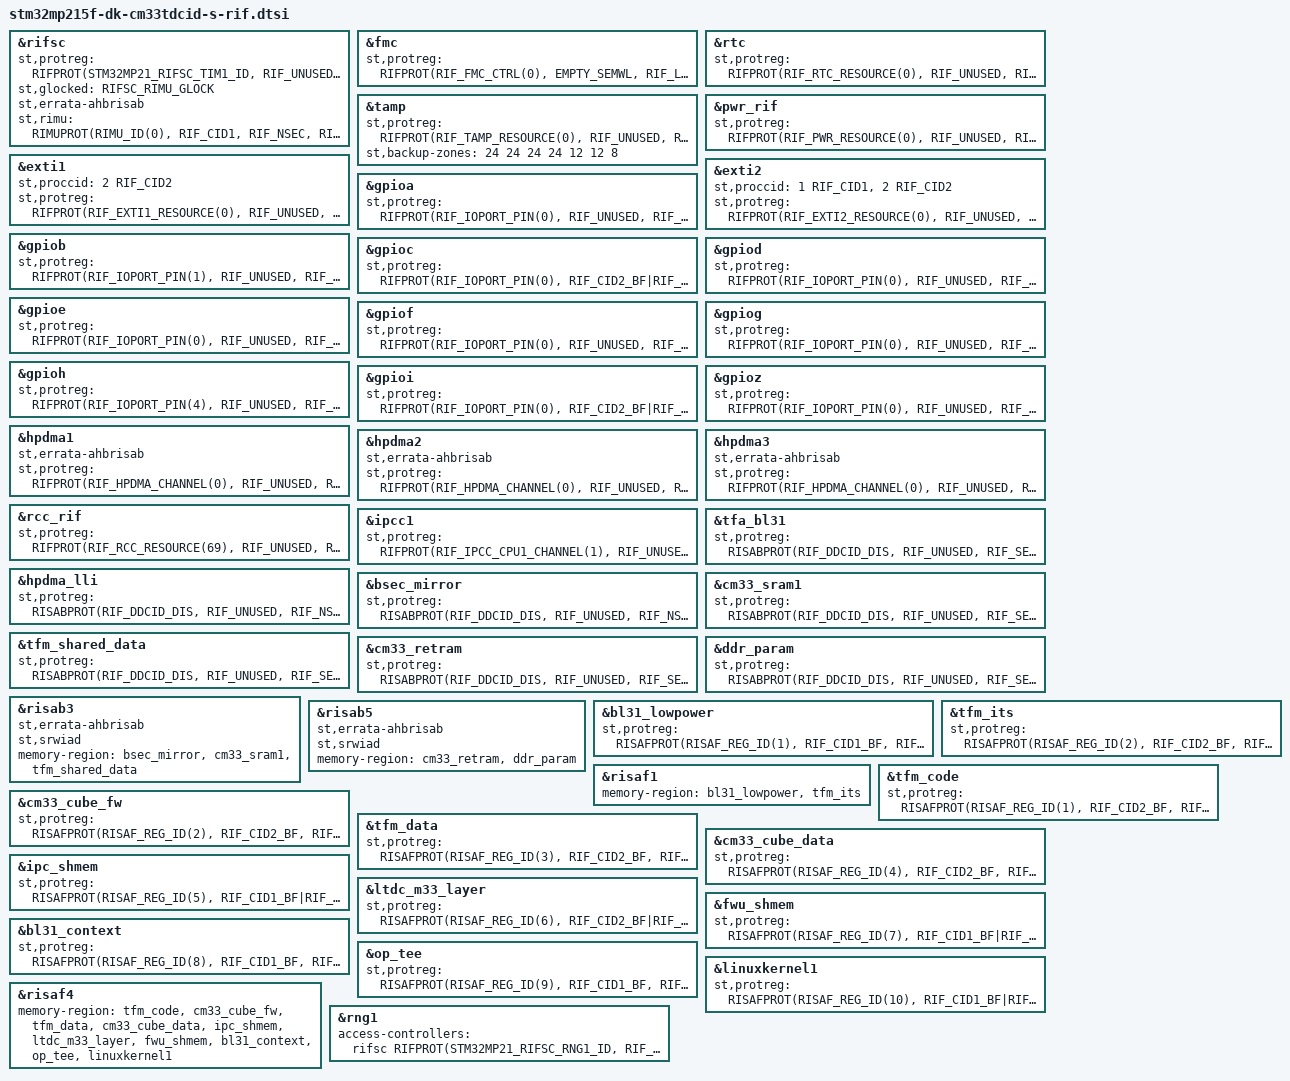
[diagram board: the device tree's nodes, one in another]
/*
 * Copyright (c) 2026, STMicroelectronics - All Rights Reserved
 *
 * SPDX-License-Identifier: Apache-2.0
 */

&rifsc {
	st,protreg = <
		RIFPROT(STM32MP21_RIFSC_TIM1_ID, RIF_UNUSED, RIF_UNLOCK, RIF_NSEC, RIF_PRIV, RIF_CID1, RIF_SEM_DIS, RIF_CFEN)
		RIFPROT(STM32MP21_RIFSC_TIM2_ID, RIF_UNUSED, RIF_UNLOCK, RIF_SEC, RIF_PRIV, RIF_CID2, RIF_SEM_DIS, RIF_CFEN)
		RIFPROT(STM32MP21_RIFSC_TIM3_ID, RIF_UNUSED, RIF_UNLOCK, RIF_NSEC, RIF_NPRIV, RIF_CID2, RIF_SEM_DIS, RIF_CFEN)
		RIFPROT(STM32MP21_RIFSC_TIM4_ID, RIF_UNUSED, RIF_UNLOCK, RIF_NSEC, RIF_PRIV, RIF_CID1, RIF_SEM_DIS, RIF_CFEN)
		RIFPROT(STM32MP21_RIFSC_TIM5_ID, RIF_UNUSED, RIF_UNLOCK, RIF_NSEC, RIF_PRIV, RIF_CID1, RIF_SEM_DIS, RIF_CFEN)
		RIFPROT(STM32MP21_RIFSC_TIM6_ID, RIF_UNUSED, RIF_UNLOCK, RIF_NSEC, RIF_NPRIV, RIF_CID2, RIF_SEM_DIS, RIF_CFEN)
		RIFPROT(STM32MP21_RIFSC_TIM7_ID, RIF_UNUSED, RIF_UNLOCK, RIF_NSEC, RIF_PRIV, RIF_CID1, RIF_SEM_DIS, RIF_CFEN)
		RIFPROT(STM32MP21_RIFSC_TIM8_ID, RIF_UNUSED, RIF_UNLOCK, RIF_NSEC, RIF_NPRIV, RIF_CID2, RIF_SEM_DIS, RIF_CFEN)
		RIFPROT(STM32MP21_RIFSC_TIM10_ID, RIF_UNUSED, RIF_UNLOCK, RIF_NSEC, RIF_PRIV, RIF_CID1, RIF_SEM_DIS, RIF_CFEN)
		RIFPROT(STM32MP21_RIFSC_TIM11_ID, RIF_UNUSED, RIF_UNLOCK, RIF_NSEC, RIF_PRIV, RIF_CID1, RIF_SEM_DIS, RIF_CFEN)
		RIFPROT(STM32MP21_RIFSC_TIM12_ID, RIF_UNUSED, RIF_UNLOCK, RIF_NSEC, RIF_PRIV, RIF_CID1, RIF_SEM_DIS, RIF_CFEN)
		RIFPROT(STM32MP21_RIFSC_TIM13_ID, RIF_UNUSED, RIF_UNLOCK, RIF_NSEC, RIF_PRIV, RIF_CID1, RIF_SEM_DIS, RIF_CFEN)
		RIFPROT(STM32MP21_RIFSC_TIM14_ID, RIF_UNUSED, RIF_UNLOCK, RIF_NSEC, RIF_PRIV, RIF_CID1, RIF_SEM_DIS, RIF_CFEN)
		RIFPROT(STM32MP21_RIFSC_TIM15_ID, RIF_UNUSED, RIF_UNLOCK, RIF_NSEC, RIF_PRIV, RIF_CID1, RIF_SEM_DIS, RIF_CFEN)
		RIFPROT(STM32MP21_RIFSC_TIM16_ID, RIF_UNUSED, RIF_UNLOCK, RIF_NSEC, RIF_PRIV, RIF_CID1, RIF_SEM_DIS, RIF_CFEN)
		RIFPROT(STM32MP21_RIFSC_TIM17_ID, RIF_UNUSED, RIF_UNLOCK, RIF_NSEC, RIF_PRIV, RIF_CID1, RIF_SEM_DIS, RIF_CFEN)
		RIFPROT(STM32MP21_RIFSC_LPTIM1_ID, RIF_UNUSED, RIF_UNLOCK, RIF_SEC, RIF_PRIV, RIF_CID2, RIF_SEM_DIS, RIF_CFEN)
		RIFPROT(STM32MP21_RIFSC_LPTIM2_ID, RIF_UNUSED, RIF_UNLOCK, RIF_NSEC, RIF_PRIV, RIF_CID1, RIF_SEM_DIS, RIF_CFEN)
		RIFPROT(STM32MP21_RIFSC_LPTIM3_ID, RIF_UNUSED, RIF_UNLOCK, RIF_NSEC, RIF_PRIV, RIF_CID1, RIF_SEM_DIS, RIF_CFEN)
		RIFPROT(STM32MP21_RIFSC_LPTIM4_ID, RIF_UNUSED, RIF_UNLOCK, RIF_NSEC, RIF_NPRIV, RIF_CID2, RIF_SEM_DIS, RIF_CFEN)
		RIFPROT(STM32MP21_RIFSC_LPTIM5_ID, RIF_UNUSED, RIF_UNLOCK, RIF_NSEC, RIF_PRIV, RIF_CID1, RIF_SEM_DIS, RIF_CFEN)
		RIFPROT(STM32MP21_RIFSC_SPI1_ID, RIF_UNUSED, RIF_UNLOCK, RIF_NSEC, RIF_NPRIV, RIF_CID2, RIF_SEM_DIS, RIF_CFEN)
		RIFPROT(STM32MP21_RIFSC_SPI2_ID, EMPTY_SEMWL, RIF_LOCK, RIF_NSEC, RIF_NPRIV, RIF_UNUSED, RIF_SEM_EN, RIF_CFEN)
		RIFPROT(STM32MP21_RIFSC_SPI3_ID, EMPTY_SEMWL, RIF_LOCK, RIF_NSEC, RIF_NPRIV, RIF_UNUSED, RIF_SEM_EN, RIF_CFEN)
		RIFPROT(STM32MP21_RIFSC_SPI4_ID, EMPTY_SEMWL, RIF_LOCK, RIF_NSEC, RIF_NPRIV, RIF_UNUSED, RIF_SEM_EN, RIF_CFEN)
		RIFPROT(STM32MP21_RIFSC_SPI5_ID, EMPTY_SEMWL, RIF_LOCK, RIF_NSEC, RIF_NPRIV, RIF_UNUSED, RIF_SEM_EN, RIF_CFEN)
		RIFPROT(STM32MP21_RIFSC_SPI6_ID, EMPTY_SEMWL, RIF_LOCK, RIF_NSEC, RIF_NPRIV, RIF_UNUSED, RIF_SEM_EN, RIF_CFEN)
		RIFPROT(STM32MP21_RIFSC_SPDIFRX_ID, EMPTY_SEMWL, RIF_LOCK, RIF_NSEC, RIF_NPRIV, RIF_UNUSED, RIF_SEM_EN, RIF_CFEN)
		RIFPROT(STM32MP21_RIFSC_USART1_ID, RIF_UNUSED, RIF_UNLOCK, RIF_NSEC, RIF_PRIV, RIF_CID1, RIF_SEM_DIS, RIF_CFEN)
		RIFPROT(STM32MP21_RIFSC_USART2_ID, RIF_UNUSED, RIF_UNLOCK, RIF_NSEC, RIF_PRIV, RIF_CID1, RIF_SEM_DIS, RIF_CFEN)
		RIFPROT(STM32MP21_RIFSC_USART3_ID, EMPTY_SEMWL, RIF_LOCK, RIF_NSEC, RIF_NPRIV, RIF_UNUSED, RIF_SEM_EN, RIF_CFEN)
		RIFPROT(STM32MP21_RIFSC_UART4_ID, RIF_UNUSED, RIF_UNLOCK, RIF_NSEC, RIF_NPRIV, RIF_CID2, RIF_SEM_DIS, RIF_CFEN)
		RIFPROT(STM32MP21_RIFSC_UART5_ID, EMPTY_SEMWL, RIF_LOCK, RIF_NSEC, RIF_NPRIV, RIF_UNUSED, RIF_SEM_EN, RIF_CFEN)
		RIFPROT(STM32MP21_RIFSC_USART6_ID, RIF_UNUSED, RIF_LOCK, RIF_NSEC, RIF_PRIV, RIF_CID1, RIF_SEM_DIS, RIF_CFEN)
		RIFPROT(STM32MP21_RIFSC_UART7_ID, EMPTY_SEMWL, RIF_LOCK, RIF_NSEC, RIF_NPRIV, RIF_UNUSED, RIF_SEM_EN, RIF_CFEN)
		RIFPROT(STM32MP21_RIFSC_LPUART1_ID, EMPTY_SEMWL, RIF_LOCK, RIF_NSEC, RIF_NPRIV, RIF_UNUSED, RIF_SEM_EN, RIF_CFEN)
		RIFPROT(STM32MP21_RIFSC_I2C1_ID, EMPTY_SEMWL, RIF_LOCK, RIF_NSEC, RIF_NPRIV, RIF_UNUSED, RIF_SEM_EN, RIF_CFEN)
		RIFPROT(STM32MP21_RIFSC_I2C2_ID, RIF_UNUSED, RIF_UNLOCK, RIF_NSEC, RIF_PRIV, RIF_CID1, RIF_SEM_DIS, RIF_CFEN)
		RIFPROT(STM32MP21_RIFSC_I2C3_ID, RIF_UNUSED, RIF_UNLOCK, RIF_SEC, RIF_PRIV, RIF_CID2, RIF_SEM_DIS, RIF_CFEN)
		RIFPROT(STM32MP21_RIFSC_SAI1_ID, RIF_UNUSED, RIF_UNLOCK, RIF_NSEC, RIF_PRIV, RIF_CID1, RIF_SEM_DIS, RIF_CFEN)
		RIFPROT(STM32MP21_RIFSC_SAI2_ID, RIF_UNUSED, RIF_UNLOCK, RIF_NSEC, RIF_PRIV, RIF_CID1, RIF_SEM_DIS, RIF_CFEN)
		RIFPROT(STM32MP21_RIFSC_SAI3_ID, EMPTY_SEMWL, RIF_LOCK, RIF_NSEC, RIF_NPRIV, RIF_UNUSED, RIF_SEM_EN, RIF_CFEN)
		RIFPROT(STM32MP21_RIFSC_SAI4_ID, EMPTY_SEMWL, RIF_LOCK, RIF_NSEC, RIF_NPRIV, RIF_UNUSED, RIF_SEM_EN, RIF_CFEN)
		RIFPROT(STM32MP21_RIFSC_MDF1_ID, RIF_UNUSED, RIF_UNLOCK, RIF_NSEC, RIF_PRIV, RIF_CID1, RIF_SEM_DIS, RIF_CFEN)
		RIFPROT(STM32MP21_RIFSC_FDCAN_ID, EMPTY_SEMWL, RIF_LOCK, RIF_NSEC, RIF_NPRIV, RIF_UNUSED, RIF_SEM_EN, RIF_CFEN)
		RIFPROT(STM32MP21_RIFSC_HDP_ID, EMPTY_SEMWL, RIF_LOCK, RIF_NSEC, RIF_NPRIV, RIF_UNUSED, RIF_SEM_EN, RIF_CFEN)
		RIFPROT(STM32MP21_RIFSC_ADC1_ID, RIF_UNUSED, RIF_UNLOCK, RIF_NSEC, RIF_PRIV, RIF_CID1, RIF_SEM_DIS, RIF_CFEN)
		RIFPROT(STM32MP21_RIFSC_ADC2_ID, RIF_UNUSED, RIF_UNLOCK, RIF_NSEC, RIF_PRIV, RIF_CID1, RIF_SEM_DIS, RIF_CFEN)
		RIFPROT(STM32MP21_RIFSC_ETH1_ID, RIF_UNUSED, RIF_UNLOCK, RIF_NSEC, RIF_PRIV, RIF_CID1, RIF_SEM_DIS, RIF_CFEN)
		RIFPROT(STM32MP21_RIFSC_ETH2_ID, EMPTY_SEMWL, RIF_LOCK, RIF_NSEC, RIF_NPRIV, RIF_UNUSED, RIF_SEM_EN, RIF_CFEN)
		RIFPROT(STM32MP21_RIFSC_USBH_ID, RIF_UNUSED, RIF_UNLOCK, RIF_NSEC, RIF_PRIV, RIF_CID1, RIF_SEM_DIS, RIF_CFEN)
		RIFPROT(STM32MP21_RIFSC_OTG_HS_ID, RIF_UNUSED, RIF_UNLOCK, RIF_NSEC, RIF_PRIV, RIF_CID1, RIF_SEM_DIS, RIF_CFEN)
		RIFPROT(STM32MP21_RIFSC_DDRPERFM_ID, RIF_UNUSED, RIF_UNLOCK, RIF_NSEC, RIF_PRIV, RIF_CID1, RIF_SEM_DIS, RIF_CFEN)
		RIFPROT(STM32MP21_RIFSC_STGEN_ID, RIF_UNUSED, RIF_UNLOCK, RIF_SEC, RIF_PRIV, RIF_CID1, RIF_SEM_DIS, RIF_CFEN)
		RIFPROT(STM32MP21_RIFSC_OCTOSPI1_ID, EMPTY_SEMWL, RIF_LOCK, RIF_NSEC, RIF_NPRIV, RIF_UNUSED, RIF_SEM_EN, RIF_CFEN)
		RIFPROT(STM32MP21_RIFSC_OTFDEC1_ID, EMPTY_SEMWL, RIF_LOCK, RIF_NSEC, RIF_NPRIV, RIF_UNUSED, RIF_SEM_EN, RIF_CFEN)
		RIFPROT(STM32MP21_RIFSC_SDMMC1_ID, RIF_UNUSED, RIF_UNLOCK, RIF_NSEC, RIF_PRIV, RIF_CID1, RIF_SEM_DIS, RIF_CFEN)
		RIFPROT(STM32MP21_RIFSC_SDMMC2_ID, RIF_UNUSED, RIF_UNLOCK, RIF_NSEC, RIF_PRIV, RIF_CID1, RIF_SEM_DIS, RIF_CFEN)
		RIFPROT(STM32MP21_RIFSC_SDMMC3_ID, RIF_UNUSED, RIF_UNLOCK, RIF_NSEC, RIF_PRIV, RIF_CID1, RIF_SEM_DIS, RIF_CFEN)
		RIFPROT(STM32MP21_RIFSC_LTDC_CMN_ID, RIF_CID1_BF|RIF_CID2_BF, RIF_UNLOCK, RIF_NSEC, RIF_NPRIV, RIF_UNUSED, RIF_SEM_EN, RIF_CFEN)
		RIFPROT(STM32MP21_RIFSC_LTDC_L1L2_ID, RIF_UNUSED, RIF_UNLOCK, RIF_NSEC, RIF_PRIV, RIF_CID1, RIF_SEM_DIS, RIF_CFEN)
		RIFPROT(STM32MP21_RIFSC_LTDC_L3_ID, RIF_UNUSED, RIF_UNLOCK, RIF_NSEC, RIF_NPRIV, RIF_CID2, RIF_SEM_DIS, RIF_CFEN)
		RIFPROT(STM32MP21_RIFSC_CSI_ID, RIF_UNUSED, RIF_UNLOCK, RIF_NSEC, RIF_PRIV, RIF_CID1, RIF_SEM_DIS, RIF_CFEN)
		RIFPROT(STM32MP21_RIFSC_DCMIPP_ID, RIF_UNUSED, RIF_UNLOCK, RIF_NSEC, RIF_PRIV, RIF_CID1, RIF_SEM_DIS, RIF_CFEN)
		RIFPROT(STM32MP21_RIFSC_DCMI_PSSI_ID, EMPTY_SEMWL, RIF_LOCK, RIF_NSEC, RIF_NPRIV, RIF_UNUSED, RIF_SEM_EN, RIF_CFEN)
		RIFPROT(STM32MP21_RIFSC_RESERVED_91_ID, RIF_CID1_BF|RIF_CID2_BF, RIF_LOCK, RIF_SEC, RIF_PRIV, RIF_UNUSED, RIF_SEM_EN, RIF_CFEN)
		RIFPROT(STM32MP21_RIFSC_RNG1_ID, RIF_CID1_BF|RIF_CID2_BF, RIF_LOCK, RIF_SEC, RIF_PRIV, RIF_UNUSED, RIF_SEM_EN, RIF_CFEN)
		RIFPROT(STM32MP21_RIFSC_RNG2_ID, RIF_UNUSED, RIF_UNLOCK, RIF_SEC, RIF_PRIV, RIF_CID1, RIF_SEM_DIS, RIF_CFEN)
		RIFPROT(STM32MP21_RIFSC_PKA_ID, RIF_CID1_BF|RIF_CID2_BF, RIF_LOCK, RIF_SEC, RIF_PRIV, RIF_UNUSED, RIF_SEM_EN, RIF_CFEN)
		RIFPROT(STM32MP21_RIFSC_SAES_ID, RIF_CID1_BF|RIF_CID2_BF, RIF_LOCK, RIF_SEC, RIF_PRIV, RIF_UNUSED, RIF_SEM_EN, RIF_CFEN)
		RIFPROT(STM32MP21_RIFSC_HASH1_ID, RIF_CID1_BF|RIF_CID2_BF, RIF_LOCK, RIF_SEC, RIF_PRIV, RIF_UNUSED, RIF_SEM_EN, RIF_CFEN)
		RIFPROT(STM32MP21_RIFSC_HASH2_ID, RIF_UNUSED, RIF_UNLOCK, RIF_SEC, RIF_PRIV, RIF_CID1, RIF_SEM_DIS, RIF_CFEN)
		RIFPROT(STM32MP21_RIFSC_CRYP1_ID, RIF_CID1_BF|RIF_CID2_BF, RIF_LOCK, RIF_SEC, RIF_PRIV, RIF_UNUSED, RIF_SEM_EN, RIF_CFEN)
		RIFPROT(STM32MP21_RIFSC_CRYP2_ID, RIF_CID1_BF|RIF_CID2_BF, RIF_UNLOCK, RIF_NSEC, RIF_NPRIV, RIF_UNUSED, RIF_SEM_EN, RIF_CFEN)
		RIFPROT(STM32MP21_RIFSC_IWDG1_ID, RIF_UNUSED, RIF_UNLOCK, RIF_SEC, RIF_PRIV, RIF_CID1, RIF_SEM_DIS, RIF_CFEN)
		RIFPROT(STM32MP21_RIFSC_IWDG2_ID, RIF_UNUSED, RIF_UNLOCK, RIF_NSEC, RIF_PRIV, RIF_CID1, RIF_SEM_DIS, RIF_CFEN)
		RIFPROT(STM32MP21_RIFSC_IWDG3_ID, RIF_UNUSED, RIF_UNLOCK, RIF_SEC, RIF_PRIV, RIF_CID2, RIF_SEM_DIS, RIF_CFEN)
		RIFPROT(STM32MP21_RIFSC_IWDG4_ID, RIF_UNUSED, RIF_UNLOCK, RIF_NSEC, RIF_NPRIV, RIF_CID2, RIF_SEM_DIS, RIF_CFEN)
		RIFPROT(STM32MP21_RIFSC_WWDG1_ID, RIF_UNUSED, RIF_UNLOCK, RIF_NSEC, RIF_NPRIV, RIF_CID2, RIF_SEM_DIS, RIF_CFEN)
		RIFPROT(STM32MP21_RIFSC_VREFBUF_ID, RIF_UNUSED, RIF_UNLOCK, RIF_SEC, RIF_PRIV, RIF_CID2, RIF_SEM_DIS, RIF_CFEN)
		RIFPROT(STM32MP21_RIFSC_DTS_ID, RIF_UNUSED, RIF_UNLOCK, RIF_NSEC, RIF_PRIV, RIF_CID1, RIF_SEM_DIS, RIF_CFEN)
		RIFPROT(STM32MP21_RIFSC_RAMCFG_ID, RIF_UNUSED, RIF_UNLOCK, RIF_SEC, RIF_PRIV, RIF_CID2, RIF_SEM_DIS, RIF_CFEN)
		RIFPROT(STM32MP21_RIFSC_CRC_ID, RIF_UNUSED, RIF_UNLOCK, RIF_SEC, RIF_PRIV, RIF_CID2, RIF_SEM_DIS, RIF_CFEN)
		RIFPROT(STM32MP21_RIFSC_SERC_ID, RIF_UNUSED, RIF_UNLOCK, RIF_SEC, RIF_PRIV, RIF_CID2, RIF_SEM_DIS, RIF_CFEN)
		RIFPROT(STM32MP21_RIFSC_I3C1_ID, RIF_UNUSED, RIF_UNLOCK, RIF_NSEC, RIF_PRIV, RIF_CID1, RIF_SEM_DIS, RIF_CFEN)
		RIFPROT(STM32MP21_RIFSC_I3C2_ID, RIF_UNUSED, RIF_UNLOCK, RIF_NSEC, RIF_NPRIV, RIF_CID2, RIF_SEM_DIS, RIF_CFEN)
		RIFPROT(STM32MP21_RIFSC_I3C3_ID, EMPTY_SEMWL, RIF_LOCK, RIF_NSEC, RIF_NPRIV, RIF_UNUSED, RIF_SEM_EN, RIF_CFEN)
		RIFPROT(STM32MP21_RIFSC_ICACHE_DCACHE_ID, RIF_UNUSED, RIF_UNLOCK, RIF_NSEC, RIF_NPRIV, RIF_CID2, RIF_SEM_DIS, RIF_CFEN)
	>;
	st,glocked = <RIFSC_RIMU_GLOCK>;
};

&fmc {
	st,protreg = <
		RIFPROT(RIF_FMC_CTRL(0), EMPTY_SEMWL, RIF_LOCK, RIF_NSEC, RIF_NPRIV, RIF_UNUSED, RIF_SEM_EN, RIF_CFEN)
		RIFPROT(RIF_FMC_CTRL(1), EMPTY_SEMWL, RIF_LOCK, RIF_NSEC, RIF_NPRIV, RIF_UNUSED, RIF_SEM_EN, RIF_CFEN)
		RIFPROT(RIF_FMC_CTRL(2), EMPTY_SEMWL, RIF_LOCK, RIF_NSEC, RIF_NPRIV, RIF_UNUSED, RIF_SEM_EN, RIF_CFEN)
		RIFPROT(RIF_FMC_CTRL(3), EMPTY_SEMWL, RIF_LOCK, RIF_NSEC, RIF_NPRIV, RIF_UNUSED, RIF_SEM_EN, RIF_CFEN)
		RIFPROT(RIF_FMC_CTRL(4), EMPTY_SEMWL, RIF_LOCK, RIF_NSEC, RIF_NPRIV, RIF_UNUSED, RIF_SEM_EN, RIF_CFEN)
		RIFPROT(RIF_FMC_CTRL(5), EMPTY_SEMWL, RIF_LOCK, RIF_NSEC, RIF_NPRIV, RIF_UNUSED, RIF_SEM_EN, RIF_CFEN)
	>;
};

&rtc {
	st,protreg = <
		RIFPROT(RIF_RTC_RESOURCE(0), RIF_UNUSED, RIF_UNLOCK, RIF_NSEC, RIF_PRIV, RIF_CID1, RIF_SEM_DIS, RIF_CFEN)
		RIFPROT(RIF_RTC_RESOURCE(1), RIF_UNUSED, RIF_UNLOCK, RIF_NSEC, RIF_NPRIV, RIF_CID2, RIF_SEM_DIS, RIF_CFEN)
		RIFPROT(RIF_RTC_RESOURCE(2), RIF_UNUSED, RIF_UNLOCK, RIF_NSEC, RIF_PRIV, RIF_CID1, RIF_SEM_DIS, RIF_CFEN)
		RIFPROT(RIF_RTC_RESOURCE(3), RIF_UNUSED, RIF_UNLOCK, RIF_NSEC, RIF_PRIV, RIF_CID1, RIF_SEM_DIS, RIF_CFEN)
		RIFPROT(RIF_RTC_RESOURCE(4), RIF_UNUSED, RIF_UNLOCK, RIF_NSEC, RIF_PRIV, RIF_CID1, RIF_SEM_DIS, RIF_CFEN)
		RIFPROT(RIF_RTC_RESOURCE(5), RIF_UNUSED, RIF_UNLOCK, RIF_NSEC, RIF_PRIV, RIF_CID1, RIF_SEM_DIS, RIF_CFEN)
	>;
};

&tamp {
	st,protreg = <
		RIFPROT(RIF_TAMP_RESOURCE(0), RIF_UNUSED, RIF_UNLOCK, RIF_SEC, RIF_PRIV, RIF_CID2, RIF_SEM_DIS, RIF_CFEN)
		RIFPROT(RIF_TAMP_RESOURCE(1), RIF_UNUSED, RIF_UNLOCK, RIF_SEC, RIF_PRIV, RIF_CID1, RIF_SEM_DIS, RIF_CFEN)
		RIFPROT(RIF_TAMP_RESOURCE(2), RIF_UNUSED, RIF_UNLOCK, RIF_SEC, RIF_PRIV, RIF_CID2, RIF_SEM_DIS, RIF_CFEN)
	>;
	st,backup-zones = <24 24 24 24 12 12 8>;
};

&pwr_rif {
	st,protreg = <
		RIFPROT(RIF_PWR_RESOURCE(0), RIF_UNUSED, RIF_UNLOCK, RIF_SEC, RIF_PRIV, RIF_CID2, RIF_SEM_DIS, RIF_CFEN)
		RIFPROT(RIF_PWR_RESOURCE(1), RIF_UNUSED, RIF_UNLOCK, RIF_SEC, RIF_PRIV, RIF_CID2, RIF_SEM_DIS, RIF_CFEN)
		RIFPROT(RIF_PWR_RESOURCE(2), RIF_UNUSED, RIF_UNLOCK, RIF_SEC, RIF_PRIV, RIF_CID1, RIF_SEM_DIS, RIF_CFEN)
		RIFPROT(RIF_PWR_RESOURCE(3), RIF_UNUSED, RIF_UNLOCK, RIF_SEC, RIF_PRIV, RIF_CID2, RIF_SEM_DIS, RIF_CFEN)
		RIFPROT(RIF_PWR_RESOURCE(5), RIF_UNUSED, RIF_UNLOCK, RIF_SEC, RIF_PRIV, RIF_CID2, RIF_SEM_DIS, RIF_CFEN)
		RIFPROT(RIF_PWR_RESOURCE(6), RIF_UNUSED, RIF_UNLOCK, RIF_SEC, RIF_PRIV, RIF_CID2, RIF_SEM_DIS, RIF_CFEN)
		RIFPROT(RIF_PWR_RESOURCE_WIO(1), RIF_UNUSED, RIF_UNLOCK, RIF_SEC, RIF_PRIV, RIF_CID2, RIF_SEM_DIS, RIF_CFEN)
		RIFPROT(RIF_PWR_RESOURCE_WIO(2), EMPTY_SEMWL, RIF_UNLOCK, RIF_NSEC, RIF_NPRIV, RIF_UNUSED, RIF_SEM_EN, RIF_CFEN)
		RIFPROT(RIF_PWR_RESOURCE_WIO(3), EMPTY_SEMWL, RIF_UNLOCK, RIF_NSEC, RIF_NPRIV, RIF_UNUSED, RIF_SEM_EN, RIF_CFEN)
		RIFPROT(RIF_PWR_RESOURCE_WIO(4), EMPTY_SEMWL, RIF_UNLOCK, RIF_NSEC, RIF_NPRIV, RIF_UNUSED, RIF_SEM_EN, RIF_CFEN)
		RIFPROT(RIF_PWR_RESOURCE_WIO(5), EMPTY_SEMWL, RIF_UNLOCK, RIF_NSEC, RIF_NPRIV, RIF_UNUSED, RIF_SEM_EN, RIF_CFEN)
		RIFPROT(RIF_PWR_RESOURCE_WIO(6), EMPTY_SEMWL, RIF_UNLOCK, RIF_NSEC, RIF_NPRIV, RIF_UNUSED, RIF_SEM_EN, RIF_CFEN)
	>;
};

&exti1 {
	st,proccid = <2 RIF_CID2>;
	st,protreg = <
		RIFPROT(RIF_EXTI1_RESOURCE(0), RIF_UNUSED, RIF_UNLOCK, RIF_NSEC, RIF_NPRIV, RIF_UNUSED, RIF_SEM_DIS, RIF_CFDIS)
		RIFPROT(RIF_EXTI1_RESOURCE(1), RIF_UNUSED, RIF_UNLOCK, RIF_NSEC, RIF_PRIV, RIF_CID1, RIF_SEM_DIS, RIF_CFEN)
		RIFPROT(RIF_EXTI1_RESOURCE(2), RIF_UNUSED, RIF_UNLOCK, RIF_NSEC, RIF_NPRIV, RIF_UNUSED, RIF_SEM_DIS, RIF_CFDIS)
		RIFPROT(RIF_EXTI1_RESOURCE(3), RIF_UNUSED, RIF_UNLOCK, RIF_NSEC, RIF_PRIV, RIF_CID1, RIF_SEM_DIS, RIF_CFEN)
		RIFPROT(RIF_EXTI1_RESOURCE(4), RIF_UNUSED, RIF_UNLOCK, RIF_NSEC, RIF_PRIV, RIF_CID1, RIF_SEM_DIS, RIF_CFEN)
		RIFPROT(RIF_EXTI1_RESOURCE(5), RIF_UNUSED, RIF_UNLOCK, RIF_NSEC, RIF_NPRIV, RIF_UNUSED, RIF_SEM_DIS, RIF_CFDIS)
		RIFPROT(RIF_EXTI1_RESOURCE(6), RIF_UNUSED, RIF_UNLOCK, RIF_NSEC, RIF_PRIV, RIF_CID1, RIF_SEM_DIS, RIF_CFEN)
		RIFPROT(RIF_EXTI1_RESOURCE(7), RIF_UNUSED, RIF_UNLOCK, RIF_NSEC, RIF_PRIV, RIF_CID1, RIF_SEM_DIS, RIF_CFEN)
		RIFPROT(RIF_EXTI1_RESOURCE(8), RIF_UNUSED, RIF_UNLOCK, RIF_NSEC, RIF_NPRIV, RIF_UNUSED, RIF_SEM_DIS, RIF_CFDIS)
		RIFPROT(RIF_EXTI1_RESOURCE(9), RIF_UNUSED, RIF_UNLOCK, RIF_NSEC, RIF_NPRIV, RIF_UNUSED, RIF_SEM_DIS, RIF_CFDIS)
		RIFPROT(RIF_EXTI1_RESOURCE(10), RIF_UNUSED, RIF_UNLOCK, RIF_NSEC, RIF_NPRIV, RIF_UNUSED, RIF_SEM_DIS, RIF_CFDIS)
		RIFPROT(RIF_EXTI1_RESOURCE(11), RIF_UNUSED, RIF_UNLOCK, RIF_NSEC, RIF_NPRIV, RIF_UNUSED, RIF_SEM_DIS, RIF_CFDIS)
		RIFPROT(RIF_EXTI1_RESOURCE(12), RIF_UNUSED, RIF_UNLOCK, RIF_NSEC, RIF_PRIV, RIF_CID1, RIF_SEM_DIS, RIF_CFEN)
		RIFPROT(RIF_EXTI1_RESOURCE(13), RIF_UNUSED, RIF_UNLOCK, RIF_NSEC, RIF_NPRIV, RIF_UNUSED, RIF_SEM_DIS, RIF_CFDIS)
		RIFPROT(RIF_EXTI1_RESOURCE(14), RIF_UNUSED, RIF_UNLOCK, RIF_NSEC, RIF_NPRIV, RIF_UNUSED, RIF_SEM_DIS, RIF_CFDIS)
		RIFPROT(RIF_EXTI1_RESOURCE(15), RIF_UNUSED, RIF_UNLOCK, RIF_NSEC, RIF_NPRIV, RIF_UNUSED, RIF_SEM_DIS, RIF_CFDIS)
		RIFPROT(RIF_EXTI1_RESOURCE(16), RIF_UNUSED, RIF_UNLOCK, RIF_NSEC, RIF_NPRIV, RIF_UNUSED, RIF_SEM_DIS, RIF_CFDIS)
		RIFPROT(RIF_EXTI1_RESOURCE(17), RIF_UNUSED, RIF_UNLOCK, RIF_NSEC, RIF_NPRIV, RIF_UNUSED, RIF_SEM_DIS, RIF_CFDIS)
		RIFPROT(RIF_EXTI1_RESOURCE(18), RIF_UNUSED, RIF_UNLOCK, RIF_NSEC, RIF_NPRIV, RIF_UNUSED, RIF_SEM_DIS, RIF_CFDIS)
		RIFPROT(RIF_EXTI1_RESOURCE(19), RIF_UNUSED, RIF_UNLOCK, RIF_NSEC, RIF_NPRIV, RIF_UNUSED, RIF_SEM_DIS, RIF_CFDIS)
		RIFPROT(RIF_EXTI1_RESOURCE(21), RIF_UNUSED, RIF_UNLOCK, RIF_NSEC, RIF_NPRIV, RIF_UNUSED, RIF_SEM_DIS, RIF_CFDIS)
		RIFPROT(RIF_EXTI1_RESOURCE(22), RIF_UNUSED, RIF_UNLOCK, RIF_NSEC, RIF_PRIV, RIF_CID1, RIF_SEM_DIS, RIF_CFEN)
		RIFPROT(RIF_EXTI1_RESOURCE(23), RIF_UNUSED, RIF_UNLOCK, RIF_SEC, RIF_PRIV, RIF_CID2, RIF_SEM_DIS, RIF_CFEN)
		RIFPROT(RIF_EXTI1_RESOURCE(26), RIF_UNUSED, RIF_UNLOCK, RIF_NSEC, RIF_PRIV, RIF_CID1, RIF_SEM_DIS, RIF_CFEN)
		RIFPROT(RIF_EXTI1_RESOURCE(27), RIF_UNUSED, RIF_UNLOCK, RIF_NSEC, RIF_PRIV, RIF_CID1, RIF_SEM_DIS, RIF_CFEN)
		RIFPROT(RIF_EXTI1_RESOURCE(28), RIF_UNUSED, RIF_UNLOCK, RIF_NSEC, RIF_NPRIV, RIF_UNUSED, RIF_SEM_DIS, RIF_CFDIS)
		RIFPROT(RIF_EXTI1_RESOURCE(29), RIF_UNUSED, RIF_UNLOCK, RIF_NSEC, RIF_PRIV, RIF_CID1, RIF_SEM_DIS, RIF_CFEN)
		RIFPROT(RIF_EXTI1_RESOURCE(30), RIF_UNUSED, RIF_UNLOCK, RIF_NSEC, RIF_NPRIV, RIF_CID2, RIF_SEM_DIS, RIF_CFEN)
		RIFPROT(RIF_EXTI1_RESOURCE(31), RIF_UNUSED, RIF_UNLOCK, RIF_NSEC, RIF_NPRIV, RIF_UNUSED, RIF_SEM_DIS, RIF_CFDIS)
		RIFPROT(RIF_EXTI1_RESOURCE(32), RIF_UNUSED, RIF_UNLOCK, RIF_NSEC, RIF_NPRIV, RIF_UNUSED, RIF_SEM_DIS, RIF_CFDIS)
		RIFPROT(RIF_EXTI1_RESOURCE(36), RIF_UNUSED, RIF_UNLOCK, RIF_NSEC, RIF_NPRIV, RIF_CID2, RIF_SEM_DIS, RIF_CFEN)
		RIFPROT(RIF_EXTI1_RESOURCE(37), RIF_UNUSED, RIF_UNLOCK, RIF_NSEC, RIF_NPRIV, RIF_UNUSED, RIF_SEM_DIS, RIF_CFDIS)
		RIFPROT(RIF_EXTI1_RESOURCE(38), RIF_UNUSED, RIF_UNLOCK, RIF_NSEC, RIF_NPRIV, RIF_UNUSED, RIF_SEM_DIS, RIF_CFDIS)
		RIFPROT(RIF_EXTI1_RESOURCE(39), RIF_UNUSED, RIF_UNLOCK, RIF_NSEC, RIF_NPRIV, RIF_UNUSED, RIF_SEM_DIS, RIF_CFDIS)
		RIFPROT(RIF_EXTI1_RESOURCE(40), RIF_UNUSED, RIF_UNLOCK, RIF_NSEC, RIF_NPRIV, RIF_UNUSED, RIF_SEM_DIS, RIF_CFDIS)
		RIFPROT(RIF_EXTI1_RESOURCE(41), RIF_UNUSED, RIF_UNLOCK, RIF_NSEC, RIF_NPRIV, RIF_UNUSED, RIF_SEM_DIS, RIF_CFDIS)
		RIFPROT(RIF_EXTI1_RESOURCE(43), RIF_UNUSED, RIF_UNLOCK, RIF_NSEC, RIF_PRIV, RIF_CID1, RIF_SEM_DIS, RIF_CFEN)
		RIFPROT(RIF_EXTI1_RESOURCE(44), RIF_UNUSED, RIF_UNLOCK, RIF_NSEC, RIF_PRIV, RIF_CID1, RIF_SEM_DIS, RIF_CFEN)
		RIFPROT(RIF_EXTI1_RESOURCE(47), RIF_UNUSED, RIF_UNLOCK, RIF_SEC, RIF_PRIV, RIF_CID2, RIF_SEM_DIS, RIF_CFEN)
		RIFPROT(RIF_EXTI1_RESOURCE(48), RIF_UNUSED, RIF_UNLOCK, RIF_NSEC, RIF_PRIV, RIF_CID1, RIF_SEM_DIS, RIF_CFEN)
		RIFPROT(RIF_EXTI1_RESOURCE(52), RIF_UNUSED, RIF_UNLOCK, RIF_SEC, RIF_PRIV, RIF_CID2, RIF_SEM_DIS, RIF_CFEN)
		RIFPROT(RIF_EXTI1_RESOURCE(53), RIF_UNUSED, RIF_UNLOCK, RIF_NSEC, RIF_NPRIV, RIF_UNUSED, RIF_SEM_DIS, RIF_CFDIS)
		RIFPROT(RIF_EXTI1_RESOURCE(54), RIF_UNUSED, RIF_UNLOCK, RIF_NSEC, RIF_NPRIV, RIF_UNUSED, RIF_SEM_DIS, RIF_CFDIS)
		RIFPROT(RIF_EXTI1_RESOURCE(55), RIF_UNUSED, RIF_UNLOCK, RIF_NSEC, RIF_NPRIV, RIF_UNUSED, RIF_SEM_DIS, RIF_CFDIS)
		RIFPROT(RIF_EXTI1_RESOURCE(56), RIF_UNUSED, RIF_UNLOCK, RIF_NSEC, RIF_NPRIV, RIF_UNUSED, RIF_SEM_DIS, RIF_CFDIS)
		RIFPROT(RIF_EXTI1_RESOURCE(57), RIF_UNUSED, RIF_UNLOCK, RIF_NSEC, RIF_NPRIV, RIF_UNUSED, RIF_SEM_DIS, RIF_CFDIS)
		RIFPROT(RIF_EXTI1_RESOURCE(59), RIF_UNUSED, RIF_UNLOCK, RIF_NSEC, RIF_PRIV, RIF_CID1, RIF_SEM_DIS, RIF_CFEN)
		RIFPROT(RIF_EXTI1_RESOURCE(60), RIF_UNUSED, RIF_UNLOCK, RIF_NSEC, RIF_NPRIV, RIF_CID2, RIF_SEM_DIS, RIF_CFEN)
		RIFPROT(RIF_EXTI1_RESOURCE(61), RIF_UNUSED, RIF_UNLOCK, RIF_SEC, RIF_PRIV, RIF_CID1, RIF_SEM_DIS, RIF_CFEN)
		RIFPROT(RIF_EXTI1_RESOURCE(62), RIF_UNUSED, RIF_UNLOCK, RIF_SEC, RIF_PRIV, RIF_CID2, RIF_SEM_DIS, RIF_CFEN)
		RIFPROT(RIF_EXTI1_RESOURCE(64), RIF_UNUSED, RIF_UNLOCK, RIF_NSEC, RIF_NPRIV, RIF_UNUSED, RIF_SEM_DIS, RIF_CFDIS)
		RIFPROT(RIF_EXTI1_RESOURCE(65), RIF_UNUSED, RIF_UNLOCK, RIF_NSEC, RIF_NPRIV, RIF_UNUSED, RIF_SEM_DIS, RIF_CFDIS)
		RIFPROT(RIF_EXTI1_RESOURCE(67), RIF_UNUSED, RIF_UNLOCK, RIF_NSEC, RIF_NPRIV, RIF_UNUSED, RIF_SEM_DIS, RIF_CFDIS)
		RIFPROT(RIF_EXTI1_RESOURCE(68), RIF_UNUSED, RIF_UNLOCK, RIF_NSEC, RIF_PRIV, RIF_CID1, RIF_SEM_DIS, RIF_CFEN)
		RIFPROT(RIF_EXTI1_RESOURCE(70), RIF_UNUSED, RIF_UNLOCK, RIF_NSEC, RIF_NPRIV, RIF_UNUSED, RIF_SEM_DIS, RIF_CFDIS)
		RIFPROT(RIF_EXTI1_RESOURCE(72), RIF_UNUSED, RIF_UNLOCK, RIF_NSEC, RIF_PRIV, RIF_CID1, RIF_SEM_DIS, RIF_CFEN)
		RIFPROT(RIF_EXTI1_RESOURCE(73), RIF_UNUSED, RIF_UNLOCK, RIF_NSEC, RIF_NPRIV, RIF_UNUSED, RIF_SEM_DIS, RIF_CFDIS)
		RIFPROT(RIF_EXTI1_RESOURCE(74), RIF_UNUSED, RIF_UNLOCK, RIF_NSEC, RIF_PRIV, RIF_CID1, RIF_SEM_DIS, RIF_CFEN)
		RIFPROT(RIF_EXTI1_RESOURCE(75), RIF_UNUSED, RIF_UNLOCK, RIF_NSEC, RIF_NPRIV, RIF_CID2, RIF_SEM_DIS, RIF_CFEN)
		RIFPROT(RIF_EXTI1_RESOURCE(76), RIF_UNUSED, RIF_UNLOCK, RIF_NSEC, RIF_NPRIV, RIF_UNUSED, RIF_SEM_DIS, RIF_CFDIS)
		RIFPROT(RIF_EXTI1_RESOURCE(77), RIF_UNUSED, RIF_UNLOCK, RIF_NSEC, RIF_PRIV, RIF_CID1, RIF_SEM_DIS, RIF_CFEN)
		RIFPROT(RIF_EXTI1_RESOURCE(78), RIF_UNUSED, RIF_UNLOCK, RIF_NSEC, RIF_PRIV, RIF_CID1, RIF_SEM_DIS, RIF_CFEN)
		RIFPROT(RIF_EXTI1_RESOURCE(79), RIF_UNUSED, RIF_UNLOCK, RIF_NSEC, RIF_PRIV, RIF_CID1, RIF_SEM_DIS, RIF_CFEN)
		RIFPROT(RIF_EXTI1_RESOURCE(80), RIF_UNUSED, RIF_UNLOCK, RIF_NSEC, RIF_NPRIV, RIF_CID2, RIF_SEM_DIS, RIF_CFEN)
		RIFPROT(RIF_EXTI1_RESOURCE(81), RIF_UNUSED, RIF_UNLOCK, RIF_NSEC, RIF_NPRIV, RIF_CID2, RIF_SEM_DIS, RIF_CFEN)
		RIFPROT(RIF_EXTI1_RESOURCE(82), RIF_UNUSED, RIF_UNLOCK, RIF_NSEC, RIF_NPRIV, RIF_CID2, RIF_SEM_DIS, RIF_CFEN)
	>;
};

&exti2 {
	st,proccid = <1 RIF_CID1>, <2 RIF_CID2>;
	st,protreg = <
		RIFPROT(RIF_EXTI2_RESOURCE(0), RIF_UNUSED, RIF_UNLOCK, RIF_NSEC, RIF_NPRIV, RIF_UNUSED, RIF_SEM_DIS, RIF_CFDIS)
		RIFPROT(RIF_EXTI2_RESOURCE(1), RIF_UNUSED, RIF_UNLOCK, RIF_NSEC, RIF_NPRIV, RIF_UNUSED, RIF_SEM_DIS, RIF_CFDIS)
		RIFPROT(RIF_EXTI2_RESOURCE(2), RIF_UNUSED, RIF_UNLOCK, RIF_NSEC, RIF_NPRIV, RIF_UNUSED, RIF_SEM_DIS, RIF_CFDIS)
		RIFPROT(RIF_EXTI2_RESOURCE(3), RIF_UNUSED, RIF_UNLOCK, RIF_NSEC, RIF_NPRIV, RIF_UNUSED, RIF_SEM_DIS, RIF_CFDIS)
		RIFPROT(RIF_EXTI2_RESOURCE(4), RIF_UNUSED, RIF_UNLOCK, RIF_NSEC, RIF_PRIV, RIF_CID1, RIF_SEM_DIS, RIF_CFEN)
		RIFPROT(RIF_EXTI2_RESOURCE(5), RIF_UNUSED, RIF_UNLOCK, RIF_NSEC, RIF_NPRIV, RIF_UNUSED, RIF_SEM_DIS, RIF_CFDIS)
		RIFPROT(RIF_EXTI2_RESOURCE(6), RIF_UNUSED, RIF_UNLOCK, RIF_NSEC, RIF_NPRIV, RIF_UNUSED, RIF_SEM_DIS, RIF_CFDIS)
		RIFPROT(RIF_EXTI2_RESOURCE(7), RIF_UNUSED, RIF_UNLOCK, RIF_NSEC, RIF_NPRIV, RIF_CID2, RIF_SEM_DIS, RIF_CFEN)
		RIFPROT(RIF_EXTI2_RESOURCE(8), RIF_UNUSED, RIF_UNLOCK, RIF_NSEC, RIF_NPRIV, RIF_UNUSED, RIF_SEM_DIS, RIF_CFDIS)
		RIFPROT(RIF_EXTI2_RESOURCE(9), RIF_UNUSED, RIF_UNLOCK, RIF_NSEC, RIF_NPRIV, RIF_UNUSED, RIF_SEM_DIS, RIF_CFDIS)
		RIFPROT(RIF_EXTI2_RESOURCE(10), RIF_UNUSED, RIF_UNLOCK, RIF_NSEC, RIF_NPRIV, RIF_UNUSED, RIF_SEM_DIS, RIF_CFDIS)
		RIFPROT(RIF_EXTI2_RESOURCE(11), RIF_UNUSED, RIF_UNLOCK, RIF_NSEC, RIF_NPRIV, RIF_UNUSED, RIF_SEM_DIS, RIF_CFDIS)
		RIFPROT(RIF_EXTI2_RESOURCE(12), RIF_UNUSED, RIF_UNLOCK, RIF_NSEC, RIF_NPRIV, RIF_UNUSED, RIF_SEM_DIS, RIF_CFDIS)
		RIFPROT(RIF_EXTI2_RESOURCE(13), RIF_UNUSED, RIF_UNLOCK, RIF_NSEC, RIF_NPRIV, RIF_UNUSED, RIF_SEM_DIS, RIF_CFDIS)
		RIFPROT(RIF_EXTI2_RESOURCE(14), RIF_UNUSED, RIF_UNLOCK, RIF_NSEC, RIF_NPRIV, RIF_UNUSED, RIF_SEM_DIS, RIF_CFDIS)
		RIFPROT(RIF_EXTI2_RESOURCE(15), RIF_UNUSED, RIF_UNLOCK, RIF_NSEC, RIF_NPRIV, RIF_UNUSED, RIF_SEM_DIS, RIF_CFDIS)
		RIFPROT(RIF_EXTI2_RESOURCE(16), RIF_UNUSED, RIF_UNLOCK, RIF_NSEC, RIF_NPRIV, RIF_UNUSED, RIF_SEM_DIS, RIF_CFDIS)
		RIFPROT(RIF_EXTI2_RESOURCE(17), RIF_UNUSED, RIF_UNLOCK, RIF_NSEC, RIF_PRIV, RIF_CID1, RIF_SEM_DIS, RIF_CFEN)
		RIFPROT(RIF_EXTI2_RESOURCE(18), RIF_UNUSED, RIF_UNLOCK, RIF_NSEC, RIF_NPRIV, RIF_CID2, RIF_SEM_DIS, RIF_CFEN)
		RIFPROT(RIF_EXTI2_RESOURCE(19), RIF_UNUSED, RIF_UNLOCK, RIF_NSEC, RIF_NPRIV, RIF_CID2, RIF_SEM_DIS, RIF_CFEN)
		RIFPROT(RIF_EXTI2_RESOURCE(21), RIF_UNUSED, RIF_UNLOCK, RIF_SEC, RIF_PRIV, RIF_CID1, RIF_SEM_DIS, RIF_CFEN)
		RIFPROT(RIF_EXTI2_RESOURCE(22), RIF_UNUSED, RIF_UNLOCK, RIF_SEC, RIF_PRIV, RIF_CID1, RIF_SEM_DIS, RIF_CFEN)
		RIFPROT(RIF_EXTI2_RESOURCE(23), RIF_UNUSED, RIF_UNLOCK, RIF_SEC, RIF_PRIV, RIF_CID2, RIF_SEM_DIS, RIF_CFEN)
		RIFPROT(RIF_EXTI2_RESOURCE(24), RIF_UNUSED, RIF_UNLOCK, RIF_SEC, RIF_PRIV, RIF_CID2, RIF_SEM_DIS, RIF_CFEN)
		RIFPROT(RIF_EXTI2_RESOURCE(26), RIF_UNUSED, RIF_UNLOCK, RIF_NSEC, RIF_NPRIV, RIF_UNUSED, RIF_SEM_DIS, RIF_CFDIS)
		RIFPROT(RIF_EXTI2_RESOURCE(29), RIF_UNUSED, RIF_UNLOCK, RIF_NSEC, RIF_PRIV, RIF_CID1, RIF_SEM_DIS, RIF_CFEN)
		RIFPROT(RIF_EXTI2_RESOURCE(30), RIF_UNUSED, RIF_UNLOCK, RIF_NSEC, RIF_NPRIV, RIF_CID2, RIF_SEM_DIS, RIF_CFEN)
		RIFPROT(RIF_EXTI2_RESOURCE(31), RIF_UNUSED, RIF_UNLOCK, RIF_NSEC, RIF_PRIV, RIF_CID1, RIF_SEM_DIS, RIF_CFEN)
		RIFPROT(RIF_EXTI2_RESOURCE(34), RIF_UNUSED, RIF_UNLOCK, RIF_NSEC, RIF_NPRIV, RIF_UNUSED, RIF_SEM_DIS, RIF_CFDIS)
		RIFPROT(RIF_EXTI2_RESOURCE(35), RIF_UNUSED, RIF_UNLOCK, RIF_NSEC, RIF_PRIV, RIF_CID1, RIF_SEM_DIS, RIF_CFEN)
		RIFPROT(RIF_EXTI2_RESOURCE(36), RIF_UNUSED, RIF_UNLOCK, RIF_SEC, RIF_PRIV, RIF_CID2, RIF_SEM_DIS, RIF_CFEN)
		RIFPROT(RIF_EXTI2_RESOURCE(37), RIF_UNUSED, RIF_UNLOCK, RIF_NSEC, RIF_NPRIV, RIF_CID2, RIF_SEM_DIS, RIF_CFEN)
		RIFPROT(RIF_EXTI2_RESOURCE(39), RIF_UNUSED, RIF_UNLOCK, RIF_SEC, RIF_PRIV, RIF_CID1, RIF_SEM_DIS, RIF_CFEN)
		RIFPROT(RIF_EXTI2_RESOURCE(40), RIF_UNUSED, RIF_UNLOCK, RIF_NSEC, RIF_PRIV, RIF_CID1, RIF_SEM_DIS, RIF_CFEN)
		RIFPROT(RIF_EXTI2_RESOURCE(41), RIF_UNUSED, RIF_UNLOCK, RIF_SEC, RIF_PRIV, RIF_CID2, RIF_SEM_DIS, RIF_CFEN)
		RIFPROT(RIF_EXTI2_RESOURCE(42), RIF_UNUSED, RIF_UNLOCK, RIF_NSEC, RIF_NPRIV, RIF_CID2, RIF_SEM_DIS, RIF_CFEN)
		RIFPROT(RIF_EXTI2_RESOURCE(49), RIF_UNUSED, RIF_UNLOCK, RIF_SEC, RIF_PRIV, RIF_CID1, RIF_SEM_DIS, RIF_CFEN)
		RIFPROT(RIF_EXTI2_RESOURCE(50), RIF_UNUSED, RIF_UNLOCK, RIF_NSEC, RIF_NPRIV, RIF_UNUSED, RIF_SEM_DIS, RIF_CFDIS)
		RIFPROT(RIF_EXTI2_RESOURCE(51), RIF_UNUSED, RIF_UNLOCK, RIF_SEC, RIF_PRIV, RIF_CID2, RIF_SEM_DIS, RIF_CFEN)
		RIFPROT(RIF_EXTI2_RESOURCE(52), RIF_UNUSED, RIF_UNLOCK, RIF_NSEC, RIF_NPRIV, RIF_UNUSED, RIF_SEM_DIS, RIF_CFDIS)
		RIFPROT(RIF_EXTI2_RESOURCE(53), RIF_UNUSED, RIF_UNLOCK, RIF_NSEC, RIF_NPRIV, RIF_UNUSED, RIF_SEM_DIS, RIF_CFDIS)
		RIFPROT(RIF_EXTI2_RESOURCE(63), RIF_UNUSED, RIF_UNLOCK, RIF_NSEC, RIF_NPRIV, RIF_UNUSED, RIF_SEM_DIS, RIF_CFDIS)
	>;
};

&gpioa {
	st,protreg = <
		RIFPROT(RIF_IOPORT_PIN(0), RIF_UNUSED, RIF_UNLOCK, RIF_SEC, RIF_PRIV, RIF_CID2, RIF_SEM_DIS, RIF_CFEN)
		RIFPROT(RIF_IOPORT_PIN(1), RIF_CID2_BF|RIF_CID1_BF , RIF_UNLOCK, RIF_NSEC, RIF_PRIV, RIF_UNUSED, RIF_SEM_EN, RIF_CFEN)
		RIFPROT(RIF_IOPORT_PIN(2), RIF_UNUSED, RIF_UNLOCK, RIF_NSEC, RIF_PRIV, RIF_CID1, RIF_SEM_DIS, RIF_CFEN)
		RIFPROT(RIF_IOPORT_PIN(3), EMPTY_SEMWL, RIF_UNLOCK, RIF_NSEC, RIF_NPRIV, RIF_UNUSED, RIF_SEM_EN, RIF_CFEN)
		RIFPROT(RIF_IOPORT_PIN(4), RIF_UNUSED, RIF_UNLOCK, RIF_NSEC, RIF_PRIV, RIF_CID1, RIF_SEM_DIS, RIF_CFEN)
		RIFPROT(RIF_IOPORT_PIN(5), RIF_UNUSED, RIF_UNLOCK, RIF_NSEC, RIF_PRIV, RIF_CID1, RIF_SEM_DIS, RIF_CFEN)
		RIFPROT(RIF_IOPORT_PIN(6), RIF_UNUSED, RIF_UNLOCK, RIF_NSEC, RIF_PRIV, RIF_CID1, RIF_SEM_DIS, RIF_CFEN)
		RIFPROT(RIF_IOPORT_PIN(7), RIF_CID2_BF|RIF_CID1_BF , RIF_UNLOCK, RIF_NSEC, RIF_PRIV, RIF_UNUSED, RIF_SEM_EN, RIF_CFEN)
		RIFPROT(RIF_IOPORT_PIN(8), RIF_UNUSED, RIF_UNLOCK, RIF_NSEC, RIF_PRIV, RIF_CID1, RIF_SEM_DIS, RIF_CFEN)
		RIFPROT(RIF_IOPORT_PIN(9), RIF_UNUSED, RIF_UNLOCK, RIF_NSEC, RIF_PRIV, RIF_CID1, RIF_SEM_DIS, RIF_CFEN)
		RIFPROT(RIF_IOPORT_PIN(10), RIF_CID2_BF|RIF_CID1_BF , RIF_UNLOCK, RIF_NSEC, RIF_PRIV, RIF_UNUSED, RIF_SEM_EN, RIF_CFEN)
		RIFPROT(RIF_IOPORT_PIN(11), RIF_UNUSED, RIF_UNLOCK, RIF_NSEC, RIF_PRIV, RIF_CID1, RIF_SEM_DIS, RIF_CFEN)
		RIFPROT(RIF_IOPORT_PIN(12), RIF_UNUSED, RIF_UNLOCK, RIF_NSEC, RIF_PRIV, RIF_CID1, RIF_SEM_DIS, RIF_CFEN)
		RIFPROT(RIF_IOPORT_PIN(13), RIF_UNUSED, RIF_UNLOCK, RIF_NSEC, RIF_PRIV, RIF_CID1, RIF_SEM_DIS, RIF_CFEN)
		RIFPROT(RIF_IOPORT_PIN(14), EMPTY_SEMWL, RIF_UNLOCK, RIF_NSEC, RIF_NPRIV, RIF_UNUSED, RIF_SEM_EN, RIF_CFEN)
		RIFPROT(RIF_IOPORT_PIN(15), RIF_UNUSED, RIF_UNLOCK, RIF_NSEC, RIF_PRIV, RIF_CID1, RIF_SEM_DIS, RIF_CFEN)
	>;
};

&gpiob {
	st,protreg = <
		RIFPROT(RIF_IOPORT_PIN(1), RIF_UNUSED, RIF_UNLOCK, RIF_NSEC, RIF_PRIV, RIF_CID1, RIF_SEM_DIS, RIF_CFEN)
		RIFPROT(RIF_IOPORT_PIN(2), RIF_UNUSED, RIF_UNLOCK, RIF_NSEC, RIF_PRIV, RIF_CID1, RIF_SEM_DIS, RIF_CFEN)
		RIFPROT(RIF_IOPORT_PIN(3), RIF_UNUSED, RIF_UNLOCK, RIF_NSEC, RIF_PRIV, RIF_CID1, RIF_SEM_DIS, RIF_CFEN)
		RIFPROT(RIF_IOPORT_PIN(5), RIF_UNUSED, RIF_UNLOCK, RIF_NSEC, RIF_PRIV, RIF_CID1, RIF_SEM_DIS, RIF_CFEN)
		RIFPROT(RIF_IOPORT_PIN(6), RIF_UNUSED, RIF_UNLOCK, RIF_NSEC, RIF_PRIV, RIF_CID1, RIF_SEM_DIS, RIF_CFEN)
		RIFPROT(RIF_IOPORT_PIN(7), RIF_UNUSED, RIF_UNLOCK, RIF_NSEC, RIF_PRIV, RIF_CID1, RIF_SEM_DIS, RIF_CFEN)
		RIFPROT(RIF_IOPORT_PIN(9), RIF_UNUSED, RIF_UNLOCK, RIF_NSEC, RIF_PRIV, RIF_CID1, RIF_SEM_DIS, RIF_CFEN)
		RIFPROT(RIF_IOPORT_PIN(10), RIF_UNUSED, RIF_UNLOCK, RIF_NSEC, RIF_PRIV, RIF_CID1, RIF_SEM_DIS, RIF_CFEN)
		RIFPROT(RIF_IOPORT_PIN(11), RIF_UNUSED, RIF_UNLOCK, RIF_NSEC, RIF_PRIV, RIF_CID1, RIF_SEM_DIS, RIF_CFEN)
		RIFPROT(RIF_IOPORT_PIN(12), RIF_UNUSED, RIF_UNLOCK, RIF_NSEC, RIF_PRIV, RIF_CID1, RIF_SEM_DIS, RIF_CFEN)
		RIFPROT(RIF_IOPORT_PIN(13), RIF_UNUSED, RIF_UNLOCK, RIF_NSEC, RIF_PRIV, RIF_CID1, RIF_SEM_DIS, RIF_CFEN)
		RIFPROT(RIF_IOPORT_PIN(14), RIF_UNUSED, RIF_UNLOCK, RIF_NSEC, RIF_PRIV, RIF_CID1, RIF_SEM_DIS, RIF_CFEN)
		RIFPROT(RIF_IOPORT_PIN(15), RIF_CID2_BF|RIF_CID1_BF , RIF_UNLOCK, RIF_NSEC, RIF_PRIV, RIF_UNUSED, RIF_SEM_EN, RIF_CFEN)
	>;
};

&gpioc {
	st,protreg = <
		RIFPROT(RIF_IOPORT_PIN(0), RIF_CID2_BF|RIF_CID1_BF , RIF_UNLOCK, RIF_NSEC, RIF_PRIV, RIF_UNUSED, RIF_SEM_EN, RIF_CFEN)
		RIFPROT(RIF_IOPORT_PIN(1), RIF_UNUSED, RIF_UNLOCK, RIF_NSEC, RIF_PRIV, RIF_CID1, RIF_SEM_DIS, RIF_CFEN)
		RIFPROT(RIF_IOPORT_PIN(2), RIF_UNUSED, RIF_UNLOCK, RIF_NSEC, RIF_PRIV, RIF_CID1, RIF_SEM_DIS, RIF_CFEN)
		RIFPROT(RIF_IOPORT_PIN(3), RIF_UNUSED, RIF_UNLOCK, RIF_NSEC, RIF_PRIV, RIF_CID1, RIF_SEM_DIS, RIF_CFEN)
		RIFPROT(RIF_IOPORT_PIN(4), RIF_UNUSED, RIF_UNLOCK, RIF_NSEC, RIF_PRIV, RIF_CID1, RIF_SEM_DIS, RIF_CFEN)
		RIFPROT(RIF_IOPORT_PIN(5), RIF_CID2_BF|RIF_CID1_BF , RIF_UNLOCK, RIF_NSEC, RIF_PRIV, RIF_UNUSED, RIF_SEM_EN, RIF_CFEN)
		RIFPROT(RIF_IOPORT_PIN(6), EMPTY_SEMWL, RIF_UNLOCK, RIF_NSEC, RIF_NPRIV, RIF_UNUSED, RIF_SEM_EN, RIF_CFEN)
		RIFPROT(RIF_IOPORT_PIN(7), RIF_UNUSED, RIF_UNLOCK, RIF_NSEC, RIF_PRIV, RIF_CID1, RIF_SEM_DIS, RIF_CFEN)
		RIFPROT(RIF_IOPORT_PIN(8), RIF_UNUSED, RIF_UNLOCK, RIF_NSEC, RIF_PRIV, RIF_CID1, RIF_SEM_DIS, RIF_CFEN)
		RIFPROT(RIF_IOPORT_PIN(9), RIF_UNUSED, RIF_UNLOCK, RIF_NSEC, RIF_PRIV, RIF_CID1, RIF_SEM_DIS, RIF_CFEN)
		RIFPROT(RIF_IOPORT_PIN(10), RIF_UNUSED, RIF_UNLOCK, RIF_NSEC, RIF_PRIV, RIF_CID1, RIF_SEM_DIS, RIF_CFEN)
		RIFPROT(RIF_IOPORT_PIN(11), RIF_CID2_BF|RIF_CID1_BF , RIF_UNLOCK, RIF_NSEC, RIF_PRIV, RIF_UNUSED, RIF_SEM_EN, RIF_CFEN)
		RIFPROT(RIF_IOPORT_PIN(12), RIF_UNUSED, RIF_UNLOCK, RIF_NSEC, RIF_NPRIV, RIF_CID2, RIF_SEM_DIS, RIF_CFEN)
		RIFPROT(RIF_IOPORT_PIN(13), RIF_UNUSED, RIF_UNLOCK, RIF_NSEC, RIF_PRIV, RIF_CID1, RIF_SEM_DIS, RIF_CFEN)
	>;
};

&gpiod {
	st,protreg = <
		RIFPROT(RIF_IOPORT_PIN(0), RIF_UNUSED, RIF_UNLOCK, RIF_NSEC, RIF_PRIV, RIF_CID1, RIF_SEM_DIS, RIF_CFEN)
		RIFPROT(RIF_IOPORT_PIN(1), RIF_UNUSED, RIF_UNLOCK, RIF_NSEC, RIF_NPRIV, RIF_CID2, RIF_SEM_DIS, RIF_CFEN)
		RIFPROT(RIF_IOPORT_PIN(2), RIF_UNUSED, RIF_UNLOCK, RIF_NSEC, RIF_NPRIV, RIF_CID2, RIF_SEM_DIS, RIF_CFEN)
		RIFPROT(RIF_IOPORT_PIN(3), RIF_UNUSED, RIF_UNLOCK, RIF_NSEC, RIF_PRIV, RIF_CID1, RIF_SEM_DIS, RIF_CFEN)
		RIFPROT(RIF_IOPORT_PIN(4), RIF_UNUSED, RIF_UNLOCK, RIF_NSEC, RIF_PRIV, RIF_CID1, RIF_SEM_DIS, RIF_CFEN)
		RIFPROT(RIF_IOPORT_PIN(5), RIF_UNUSED, RIF_UNLOCK, RIF_NSEC, RIF_PRIV, RIF_CID1, RIF_SEM_DIS, RIF_CFEN)
		RIFPROT(RIF_IOPORT_PIN(6), RIF_UNUSED, RIF_UNLOCK, RIF_NSEC, RIF_PRIV, RIF_CID1, RIF_SEM_DIS, RIF_CFEN)
		RIFPROT(RIF_IOPORT_PIN(7), EMPTY_SEMWL, RIF_UNLOCK, RIF_NSEC, RIF_NPRIV, RIF_UNUSED, RIF_SEM_EN, RIF_CFEN)
		RIFPROT(RIF_IOPORT_PIN(8), RIF_UNUSED, RIF_UNLOCK, RIF_NSEC, RIF_PRIV, RIF_CID1, RIF_SEM_DIS, RIF_CFEN)
		RIFPROT(RIF_IOPORT_PIN(9), RIF_UNUSED, RIF_UNLOCK, RIF_NSEC, RIF_PRIV, RIF_CID1, RIF_SEM_DIS, RIF_CFEN)
		RIFPROT(RIF_IOPORT_PIN(10), RIF_UNUSED, RIF_UNLOCK, RIF_NSEC, RIF_PRIV, RIF_CID1, RIF_SEM_DIS, RIF_CFEN)
		RIFPROT(RIF_IOPORT_PIN(11), RIF_UNUSED, RIF_UNLOCK, RIF_NSEC, RIF_NPRIV, RIF_CID2, RIF_SEM_DIS, RIF_CFEN)
		RIFPROT(RIF_IOPORT_PIN(12), RIF_UNUSED, RIF_UNLOCK, RIF_NSEC, RIF_PRIV, RIF_CID1, RIF_SEM_DIS, RIF_CFEN)
		RIFPROT(RIF_IOPORT_PIN(13), RIF_UNUSED, RIF_UNLOCK, RIF_NSEC, RIF_PRIV, RIF_CID1, RIF_SEM_DIS, RIF_CFEN)
		RIFPROT(RIF_IOPORT_PIN(14), RIF_UNUSED, RIF_UNLOCK, RIF_NSEC, RIF_PRIV, RIF_CID1, RIF_SEM_DIS, RIF_CFEN)
		RIFPROT(RIF_IOPORT_PIN(15), RIF_UNUSED, RIF_UNLOCK, RIF_NSEC, RIF_PRIV, RIF_CID1, RIF_SEM_DIS, RIF_CFEN)
	>;
};

&gpioe {
	st,protreg = <
		RIFPROT(RIF_IOPORT_PIN(0), RIF_UNUSED, RIF_UNLOCK, RIF_NSEC, RIF_PRIV, RIF_CID1, RIF_SEM_DIS, RIF_CFEN)
		RIFPROT(RIF_IOPORT_PIN(1), RIF_UNUSED, RIF_UNLOCK, RIF_NSEC, RIF_PRIV, RIF_CID1, RIF_SEM_DIS, RIF_CFEN)
		RIFPROT(RIF_IOPORT_PIN(2), RIF_UNUSED, RIF_UNLOCK, RIF_NSEC, RIF_PRIV, RIF_CID1, RIF_SEM_DIS, RIF_CFEN)
		RIFPROT(RIF_IOPORT_PIN(3), RIF_UNUSED, RIF_UNLOCK, RIF_NSEC, RIF_PRIV, RIF_CID1, RIF_SEM_DIS, RIF_CFEN)
		RIFPROT(RIF_IOPORT_PIN(4), RIF_UNUSED, RIF_UNLOCK, RIF_NSEC, RIF_PRIV, RIF_CID1, RIF_SEM_DIS, RIF_CFEN)
		RIFPROT(RIF_IOPORT_PIN(5), RIF_UNUSED, RIF_UNLOCK, RIF_NSEC, RIF_PRIV, RIF_CID1, RIF_SEM_DIS, RIF_CFEN)
		RIFPROT(RIF_IOPORT_PIN(6), EMPTY_SEMWL, RIF_UNLOCK, RIF_NSEC, RIF_NPRIV, RIF_UNUSED, RIF_SEM_EN, RIF_CFEN)
		RIFPROT(RIF_IOPORT_PIN(7), EMPTY_SEMWL, RIF_UNLOCK, RIF_NSEC, RIF_NPRIV, RIF_UNUSED, RIF_SEM_EN, RIF_CFEN)
		RIFPROT(RIF_IOPORT_PIN(8), RIF_UNUSED, RIF_UNLOCK, RIF_NSEC, RIF_PRIV, RIF_CID1, RIF_SEM_DIS, RIF_CFEN)
		RIFPROT(RIF_IOPORT_PIN(9), EMPTY_SEMWL, RIF_UNLOCK, RIF_NSEC, RIF_NPRIV, RIF_UNUSED, RIF_SEM_EN, RIF_CFEN)
		RIFPROT(RIF_IOPORT_PIN(10), EMPTY_SEMWL, RIF_UNLOCK, RIF_NSEC, RIF_NPRIV, RIF_UNUSED, RIF_SEM_EN, RIF_CFEN)
		RIFPROT(RIF_IOPORT_PIN(11), RIF_UNUSED, RIF_UNLOCK, RIF_NSEC, RIF_PRIV, RIF_CID1, RIF_SEM_DIS, RIF_CFEN)
		RIFPROT(RIF_IOPORT_PIN(12), RIF_UNUSED, RIF_UNLOCK, RIF_NSEC, RIF_PRIV, RIF_CID1, RIF_SEM_DIS, RIF_CFEN)
		RIFPROT(RIF_IOPORT_PIN(13), RIF_UNUSED, RIF_UNLOCK, RIF_NSEC, RIF_PRIV, RIF_CID1, RIF_SEM_DIS, RIF_CFEN)
		RIFPROT(RIF_IOPORT_PIN(14), RIF_UNUSED, RIF_UNLOCK, RIF_NSEC, RIF_PRIV, RIF_CID1, RIF_SEM_DIS, RIF_CFEN)
		RIFPROT(RIF_IOPORT_PIN(15), RIF_UNUSED, RIF_UNLOCK, RIF_NSEC, RIF_PRIV, RIF_CID1, RIF_SEM_DIS, RIF_CFEN)
	>;
};

&gpiof {
	st,protreg = <
		RIFPROT(RIF_IOPORT_PIN(0), RIF_UNUSED, RIF_UNLOCK, RIF_NSEC, RIF_PRIV, RIF_CID1, RIF_SEM_DIS, RIF_CFEN)
		RIFPROT(RIF_IOPORT_PIN(1), RIF_UNUSED, RIF_UNLOCK, RIF_NSEC, RIF_PRIV, RIF_CID1, RIF_SEM_DIS, RIF_CFEN)
		RIFPROT(RIF_IOPORT_PIN(2), RIF_UNUSED, RIF_UNLOCK, RIF_NSEC, RIF_PRIV, RIF_CID1, RIF_SEM_DIS, RIF_CFEN)
		RIFPROT(RIF_IOPORT_PIN(3), RIF_UNUSED, RIF_UNLOCK, RIF_NSEC, RIF_PRIV, RIF_CID1, RIF_SEM_DIS, RIF_CFEN)
		RIFPROT(RIF_IOPORT_PIN(4), RIF_UNUSED, RIF_UNLOCK, RIF_NSEC, RIF_PRIV, RIF_CID1, RIF_SEM_DIS, RIF_CFEN)
		RIFPROT(RIF_IOPORT_PIN(5), RIF_CID2_BF|RIF_CID1_BF , RIF_UNLOCK, RIF_NSEC, RIF_PRIV, RIF_UNUSED, RIF_SEM_EN, RIF_CFEN)
		RIFPROT(RIF_IOPORT_PIN(6), RIF_UNUSED, RIF_UNLOCK, RIF_SEC, RIF_PRIV, RIF_CID2, RIF_SEM_DIS, RIF_CFEN)
		RIFPROT(RIF_IOPORT_PIN(7), RIF_UNUSED, RIF_UNLOCK, RIF_NSEC, RIF_NPRIV, RIF_CID2, RIF_SEM_DIS, RIF_CFEN)
		RIFPROT(RIF_IOPORT_PIN(8), RIF_UNUSED, RIF_UNLOCK, RIF_NSEC, RIF_PRIV, RIF_CID1, RIF_SEM_DIS, RIF_CFEN)
		RIFPROT(RIF_IOPORT_PIN(9), RIF_CID2_BF|RIF_CID1_BF , RIF_UNLOCK, RIF_NSEC, RIF_PRIV, RIF_UNUSED, RIF_SEM_EN, RIF_CFEN)
		RIFPROT(RIF_IOPORT_PIN(10), RIF_UNUSED, RIF_UNLOCK, RIF_NSEC, RIF_PRIV, RIF_CID1, RIF_SEM_DIS, RIF_CFEN)
		RIFPROT(RIF_IOPORT_PIN(11), RIF_UNUSED, RIF_UNLOCK, RIF_SEC, RIF_PRIV, RIF_CID2, RIF_SEM_DIS, RIF_CFEN)
		RIFPROT(RIF_IOPORT_PIN(12), RIF_CID2_BF|RIF_CID1_BF , RIF_UNLOCK, RIF_NSEC, RIF_PRIV, RIF_UNUSED, RIF_SEM_EN, RIF_CFEN)
		RIFPROT(RIF_IOPORT_PIN(13), RIF_UNUSED, RIF_UNLOCK, RIF_NSEC, RIF_PRIV, RIF_CID1, RIF_SEM_DIS, RIF_CFEN)
		RIFPROT(RIF_IOPORT_PIN(15), RIF_UNUSED, RIF_UNLOCK, RIF_NSEC, RIF_PRIV, RIF_CID1, RIF_SEM_DIS, RIF_CFEN)
	>;
};

&gpiog {
	st,protreg = <
		RIFPROT(RIF_IOPORT_PIN(0), RIF_UNUSED, RIF_UNLOCK, RIF_NSEC, RIF_NPRIV, RIF_CID2, RIF_SEM_DIS, RIF_CFEN)
		RIFPROT(RIF_IOPORT_PIN(1), RIF_UNUSED, RIF_UNLOCK, RIF_NSEC, RIF_PRIV, RIF_CID1, RIF_SEM_DIS, RIF_CFEN)
		RIFPROT(RIF_IOPORT_PIN(2), RIF_CID2_BF|RIF_CID1_BF , RIF_UNLOCK, RIF_NSEC, RIF_PRIV, RIF_UNUSED, RIF_SEM_EN, RIF_CFEN)
		RIFPROT(RIF_IOPORT_PIN(3), EMPTY_SEMWL, RIF_UNLOCK, RIF_NSEC, RIF_NPRIV, RIF_UNUSED, RIF_SEM_EN, RIF_CFEN)
		RIFPROT(RIF_IOPORT_PIN(4), RIF_CID2_BF|RIF_CID1_BF , RIF_UNLOCK, RIF_NSEC, RIF_PRIV, RIF_UNUSED, RIF_SEM_EN, RIF_CFEN)
		RIFPROT(RIF_IOPORT_PIN(5), RIF_CID2_BF|RIF_CID1_BF , RIF_UNLOCK, RIF_NSEC, RIF_PRIV, RIF_UNUSED, RIF_SEM_EN, RIF_CFEN)
		RIFPROT(RIF_IOPORT_PIN(7), RIF_CID2_BF|RIF_CID1_BF , RIF_UNLOCK, RIF_NSEC, RIF_PRIV, RIF_UNUSED, RIF_SEM_EN, RIF_CFEN)
		RIFPROT(RIF_IOPORT_PIN(8), RIF_CID2_BF|RIF_CID1_BF , RIF_UNLOCK, RIF_NSEC, RIF_PRIV, RIF_UNUSED, RIF_SEM_EN, RIF_CFEN)
		RIFPROT(RIF_IOPORT_PIN(9),RIF_CID2_BF|RIF_CID1_BF , RIF_UNLOCK, RIF_NSEC, RIF_PRIV, RIF_UNUSED, RIF_SEM_EN, RIF_CFEN)
		RIFPROT(RIF_IOPORT_PIN(10), RIF_CID2_BF|RIF_CID1_BF , RIF_UNLOCK, RIF_NSEC, RIF_PRIV, RIF_UNUSED, RIF_SEM_EN, RIF_CFEN)
		RIFPROT(RIF_IOPORT_PIN(11), RIF_CID2_BF|RIF_CID1_BF , RIF_UNLOCK, RIF_NSEC, RIF_PRIV, RIF_UNUSED, RIF_SEM_EN, RIF_CFEN)
		RIFPROT(RIF_IOPORT_PIN(12), RIF_CID2_BF|RIF_CID1_BF , RIF_UNLOCK, RIF_NSEC, RIF_PRIV, RIF_UNUSED, RIF_SEM_EN, RIF_CFEN)
		RIFPROT(RIF_IOPORT_PIN(13), RIF_UNUSED, RIF_UNLOCK, RIF_NSEC, RIF_PRIV, RIF_CID1, RIF_SEM_DIS, RIF_CFEN)
		RIFPROT(RIF_IOPORT_PIN(14), RIF_UNUSED, RIF_UNLOCK, RIF_NSEC, RIF_PRIV, RIF_CID1, RIF_SEM_DIS, RIF_CFEN)
		RIFPROT(RIF_IOPORT_PIN(15), RIF_CID2_BF|RIF_CID1_BF , RIF_UNLOCK, RIF_NSEC, RIF_PRIV, RIF_UNUSED, RIF_SEM_EN, RIF_CFEN)
	>;
};

&gpioh {
	st,protreg = <
		RIFPROT(RIF_IOPORT_PIN(4), RIF_UNUSED, RIF_UNLOCK, RIF_SEC, RIF_PRIV, RIF_CID1, RIF_SEM_DIS, RIF_CFEN)
		RIFPROT(RIF_IOPORT_PIN(5), RIF_UNUSED, RIF_UNLOCK, RIF_NSEC, RIF_PRIV, RIF_CID1, RIF_SEM_DIS, RIF_CFEN)
		RIFPROT(RIF_IOPORT_PIN(7), RIF_UNUSED, RIF_UNLOCK, RIF_NSEC, RIF_NPRIV, RIF_CID2, RIF_SEM_DIS, RIF_CFEN)
		RIFPROT(RIF_IOPORT_PIN(8), RIF_UNUSED, RIF_UNLOCK, RIF_NSEC, RIF_NPRIV, RIF_CID2, RIF_SEM_DIS, RIF_CFEN)
		RIFPROT(RIF_IOPORT_PIN(9), RIF_UNUSED, RIF_UNLOCK, RIF_NSEC, RIF_PRIV, RIF_CID1, RIF_SEM_DIS, RIF_CFEN)
		RIFPROT(RIF_IOPORT_PIN(10), EMPTY_SEMWL, RIF_UNLOCK, RIF_NSEC, RIF_NPRIV, RIF_UNUSED, RIF_SEM_EN, RIF_CFEN)
		RIFPROT(RIF_IOPORT_PIN(11), RIF_UNUSED, RIF_UNLOCK, RIF_NSEC, RIF_PRIV, RIF_CID1, RIF_SEM_DIS, RIF_CFEN)
		RIFPROT(RIF_IOPORT_PIN(12), RIF_UNUSED, RIF_UNLOCK, RIF_NSEC, RIF_NPRIV, RIF_CID2, RIF_SEM_DIS, RIF_CFEN)
		RIFPROT(RIF_IOPORT_PIN(13), RIF_UNUSED, RIF_UNLOCK, RIF_NSEC, RIF_PRIV, RIF_CID1, RIF_SEM_DIS, RIF_CFEN)
	>;
};

&gpioi {
	st,protreg = <
		RIFPROT(RIF_IOPORT_PIN(0), RIF_CID2_BF|RIF_CID1_BF , RIF_UNLOCK, RIF_NSEC, RIF_PRIV, RIF_UNUSED, RIF_SEM_EN, RIF_CFEN)
		RIFPROT(RIF_IOPORT_PIN(1), RIF_CID2_BF|RIF_CID1_BF , RIF_UNLOCK, RIF_NSEC, RIF_PRIV, RIF_UNUSED, RIF_SEM_EN, RIF_CFEN)
		RIFPROT(RIF_IOPORT_PIN(4), RIF_CID2_BF|RIF_CID1_BF , RIF_UNLOCK, RIF_NSEC, RIF_PRIV, RIF_UNUSED, RIF_SEM_EN, RIF_CFEN)
		RIFPROT(RIF_IOPORT_PIN(5), RIF_UNUSED, RIF_UNLOCK, RIF_NSEC, RIF_NPRIV, RIF_CID2, RIF_SEM_DIS, RIF_CFEN)
		RIFPROT(RIF_IOPORT_PIN(6), RIF_CID2_BF|RIF_CID1_BF , RIF_UNLOCK, RIF_NSEC, RIF_PRIV, RIF_UNUSED, RIF_SEM_EN, RIF_CFEN)
		RIFPROT(RIF_IOPORT_PIN(8), RIF_CID2_BF|RIF_CID1_BF , RIF_UNLOCK, RIF_NSEC, RIF_PRIV, RIF_UNUSED, RIF_SEM_EN, RIF_CFEN)
	>;
};

&gpioz {
	st,protreg = <
		RIFPROT(RIF_IOPORT_PIN(0), RIF_UNUSED, RIF_UNLOCK, RIF_SEC, RIF_PRIV, RIF_CID2, RIF_SEM_DIS, RIF_CFEN)
		RIFPROT(RIF_IOPORT_PIN(1), RIF_UNUSED, RIF_UNLOCK, RIF_SEC, RIF_PRIV, RIF_CID2, RIF_SEM_DIS, RIF_CFEN)
		RIFPROT(RIF_IOPORT_PIN(3), RIF_UNUSED, RIF_UNLOCK, RIF_NSEC, RIF_PRIV, RIF_CID1, RIF_SEM_DIS, RIF_CFEN)
	>;
};

&hpdma1 {
	st,errata-ahbrisab;
	st,protreg = <
		RIFPROT(RIF_HPDMA_CHANNEL(0), RIF_UNUSED, RIF_LOCK, RIF_NSEC, RIF_PRIV, RIF_CID1, RIF_SEM_DIS, RIF_CFEN)
		RIFPROT(RIF_HPDMA_CHANNEL(1), RIF_UNUSED, RIF_LOCK, RIF_NSEC, RIF_PRIV, RIF_CID1, RIF_SEM_DIS, RIF_CFEN)
		RIFPROT(RIF_HPDMA_CHANNEL(2), RIF_UNUSED, RIF_LOCK, RIF_NSEC, RIF_PRIV, RIF_CID1, RIF_SEM_DIS, RIF_CFEN)
		RIFPROT(RIF_HPDMA_CHANNEL(3), RIF_UNUSED, RIF_LOCK, RIF_NSEC, RIF_PRIV, RIF_CID1, RIF_SEM_DIS, RIF_CFEN)
		RIFPROT(RIF_HPDMA_CHANNEL(4), RIF_UNUSED, RIF_LOCK, RIF_NSEC, RIF_PRIV, RIF_CID1, RIF_SEM_DIS, RIF_CFEN)
		RIFPROT(RIF_HPDMA_CHANNEL(5), RIF_UNUSED, RIF_LOCK, RIF_NSEC, RIF_PRIV, RIF_CID1, RIF_SEM_DIS, RIF_CFEN)
		RIFPROT(RIF_HPDMA_CHANNEL(6), RIF_UNUSED, RIF_LOCK, RIF_NSEC, RIF_PRIV, RIF_CID1, RIF_SEM_DIS, RIF_CFEN)
		RIFPROT(RIF_HPDMA_CHANNEL(7), RIF_UNUSED, RIF_LOCK, RIF_NSEC, RIF_PRIV, RIF_CID1, RIF_SEM_DIS, RIF_CFEN)
		RIFPROT(RIF_HPDMA_CHANNEL(8), RIF_UNUSED, RIF_LOCK, RIF_NSEC, RIF_PRIV, RIF_CID1, RIF_SEM_DIS, RIF_CFEN)
		RIFPROT(RIF_HPDMA_CHANNEL(9), RIF_UNUSED, RIF_LOCK, RIF_NSEC, RIF_PRIV, RIF_CID1, RIF_SEM_DIS, RIF_CFEN)
		RIFPROT(RIF_HPDMA_CHANNEL(10), RIF_UNUSED, RIF_LOCK, RIF_NSEC, RIF_PRIV, RIF_CID1, RIF_SEM_DIS, RIF_CFEN)
		RIFPROT(RIF_HPDMA_CHANNEL(11), RIF_UNUSED, RIF_LOCK, RIF_NSEC, RIF_PRIV, RIF_CID1, RIF_SEM_DIS, RIF_CFEN)
		RIFPROT(RIF_HPDMA_CHANNEL(12), RIF_UNUSED, RIF_LOCK, RIF_NSEC, RIF_PRIV, RIF_CID1, RIF_SEM_DIS, RIF_CFEN)
		RIFPROT(RIF_HPDMA_CHANNEL(13), RIF_UNUSED, RIF_LOCK, RIF_NSEC, RIF_PRIV, RIF_CID1, RIF_SEM_DIS, RIF_CFEN)
		RIFPROT(RIF_HPDMA_CHANNEL(14), RIF_UNUSED, RIF_LOCK, RIF_NSEC, RIF_PRIV, RIF_CID1, RIF_SEM_DIS, RIF_CFEN)
		RIFPROT(RIF_HPDMA_CHANNEL(15), RIF_UNUSED, RIF_LOCK, RIF_NSEC, RIF_PRIV, RIF_CID1, RIF_SEM_DIS, RIF_CFEN)
	>;
};

&hpdma2 {
	st,errata-ahbrisab;
	st,protreg = <
		RIFPROT(RIF_HPDMA_CHANNEL(0), RIF_UNUSED, RIF_LOCK, RIF_NSEC, RIF_PRIV, RIF_CID1, RIF_SEM_DIS, RIF_CFEN)
		RIFPROT(RIF_HPDMA_CHANNEL(1), RIF_UNUSED, RIF_LOCK, RIF_NSEC, RIF_PRIV, RIF_CID1, RIF_SEM_DIS, RIF_CFEN)
		RIFPROT(RIF_HPDMA_CHANNEL(2), RIF_UNUSED, RIF_LOCK, RIF_NSEC, RIF_PRIV, RIF_CID1, RIF_SEM_DIS, RIF_CFEN)
		RIFPROT(RIF_HPDMA_CHANNEL(3), RIF_UNUSED, RIF_LOCK, RIF_NSEC, RIF_PRIV, RIF_CID1, RIF_SEM_DIS, RIF_CFEN)
		RIFPROT(RIF_HPDMA_CHANNEL(4), RIF_UNUSED, RIF_LOCK, RIF_NSEC, RIF_PRIV, RIF_CID1, RIF_SEM_DIS, RIF_CFEN)
		RIFPROT(RIF_HPDMA_CHANNEL(5), RIF_UNUSED, RIF_LOCK, RIF_NSEC, RIF_PRIV, RIF_CID1, RIF_SEM_DIS, RIF_CFEN)
		RIFPROT(RIF_HPDMA_CHANNEL(6), RIF_UNUSED, RIF_LOCK, RIF_NSEC, RIF_PRIV, RIF_CID1, RIF_SEM_DIS, RIF_CFEN)
		RIFPROT(RIF_HPDMA_CHANNEL(7), RIF_UNUSED, RIF_LOCK, RIF_NSEC, RIF_PRIV, RIF_CID1, RIF_SEM_DIS, RIF_CFEN)
		RIFPROT(RIF_HPDMA_CHANNEL(8), RIF_UNUSED, RIF_LOCK, RIF_NSEC, RIF_PRIV, RIF_CID1, RIF_SEM_DIS, RIF_CFEN)
		RIFPROT(RIF_HPDMA_CHANNEL(9), RIF_UNUSED, RIF_LOCK, RIF_NSEC, RIF_PRIV, RIF_CID1, RIF_SEM_DIS, RIF_CFEN)
		RIFPROT(RIF_HPDMA_CHANNEL(10), RIF_UNUSED, RIF_LOCK, RIF_NSEC, RIF_PRIV, RIF_CID1, RIF_SEM_DIS, RIF_CFEN)
		RIFPROT(RIF_HPDMA_CHANNEL(11), RIF_UNUSED, RIF_LOCK, RIF_NSEC, RIF_PRIV, RIF_CID1, RIF_SEM_DIS, RIF_CFEN)
		RIFPROT(RIF_HPDMA_CHANNEL(12), RIF_UNUSED, RIF_LOCK, RIF_NSEC, RIF_PRIV, RIF_CID1, RIF_SEM_DIS, RIF_CFEN)
		RIFPROT(RIF_HPDMA_CHANNEL(13), RIF_UNUSED, RIF_LOCK, RIF_NSEC, RIF_PRIV, RIF_CID1, RIF_SEM_DIS, RIF_CFEN)
		RIFPROT(RIF_HPDMA_CHANNEL(14), RIF_UNUSED, RIF_LOCK, RIF_NSEC, RIF_PRIV, RIF_CID1, RIF_SEM_DIS, RIF_CFEN)
		RIFPROT(RIF_HPDMA_CHANNEL(15), RIF_UNUSED, RIF_LOCK, RIF_NSEC, RIF_PRIV, RIF_CID1, RIF_SEM_DIS, RIF_CFEN)
	>;
};

&hpdma3 {
	st,errata-ahbrisab;
	st,protreg = <
		RIFPROT(RIF_HPDMA_CHANNEL(0), RIF_UNUSED, RIF_LOCK, RIF_NSEC, RIF_NPRIV, RIF_CID2, RIF_SEM_DIS, RIF_CFEN)
		RIFPROT(RIF_HPDMA_CHANNEL(1), RIF_UNUSED, RIF_LOCK, RIF_NSEC, RIF_NPRIV, RIF_CID2, RIF_SEM_DIS, RIF_CFEN)
		RIFPROT(RIF_HPDMA_CHANNEL(2), RIF_UNUSED, RIF_LOCK, RIF_NSEC, RIF_NPRIV, RIF_CID2, RIF_SEM_DIS, RIF_CFEN)
		RIFPROT(RIF_HPDMA_CHANNEL(3), RIF_UNUSED, RIF_LOCK, RIF_NSEC, RIF_NPRIV, RIF_CID2, RIF_SEM_DIS, RIF_CFEN)
		RIFPROT(RIF_HPDMA_CHANNEL(4), RIF_UNUSED, RIF_LOCK, RIF_NSEC, RIF_NPRIV, RIF_CID2, RIF_SEM_DIS, RIF_CFEN)
		RIFPROT(RIF_HPDMA_CHANNEL(5), RIF_UNUSED, RIF_LOCK, RIF_NSEC, RIF_NPRIV, RIF_CID2, RIF_SEM_DIS, RIF_CFEN)
		RIFPROT(RIF_HPDMA_CHANNEL(6), RIF_UNUSED, RIF_LOCK, RIF_NSEC, RIF_NPRIV, RIF_CID2, RIF_SEM_DIS, RIF_CFEN)
		RIFPROT(RIF_HPDMA_CHANNEL(7), RIF_UNUSED, RIF_LOCK, RIF_NSEC, RIF_NPRIV, RIF_CID2, RIF_SEM_DIS, RIF_CFEN)
		RIFPROT(RIF_HPDMA_CHANNEL(8), RIF_UNUSED, RIF_LOCK, RIF_NSEC, RIF_NPRIV, RIF_CID2, RIF_SEM_DIS, RIF_CFEN)
		RIFPROT(RIF_HPDMA_CHANNEL(9), RIF_UNUSED, RIF_LOCK, RIF_NSEC, RIF_NPRIV, RIF_CID2, RIF_SEM_DIS, RIF_CFEN)
		RIFPROT(RIF_HPDMA_CHANNEL(10), RIF_UNUSED, RIF_LOCK, RIF_NSEC, RIF_NPRIV, RIF_CID2, RIF_SEM_DIS, RIF_CFEN)
		RIFPROT(RIF_HPDMA_CHANNEL(11), RIF_UNUSED, RIF_LOCK, RIF_NSEC, RIF_NPRIV, RIF_CID2, RIF_SEM_DIS, RIF_CFEN)
		RIFPROT(RIF_HPDMA_CHANNEL(12), RIF_UNUSED, RIF_LOCK, RIF_NSEC, RIF_NPRIV, RIF_CID2, RIF_SEM_DIS, RIF_CFEN)
		RIFPROT(RIF_HPDMA_CHANNEL(13), RIF_UNUSED, RIF_LOCK, RIF_NSEC, RIF_NPRIV, RIF_CID2, RIF_SEM_DIS, RIF_CFEN)
		RIFPROT(RIF_HPDMA_CHANNEL(14), RIF_UNUSED, RIF_LOCK, RIF_NSEC, RIF_NPRIV, RIF_CID2, RIF_SEM_DIS, RIF_CFEN)
		RIFPROT(RIF_HPDMA_CHANNEL(15), RIF_UNUSED, RIF_LOCK, RIF_NSEC, RIF_NPRIV, RIF_CID2, RIF_SEM_DIS, RIF_CFEN)
	>;
};

&rifsc {
	st,errata-ahbrisab;
	st,rimu = <
		RIMUPROT(RIMU_ID(0), RIF_CID1, RIF_NSEC, RIF_PRIV, RIF_CIDSEL_M)
		RIMUPROT(RIMU_ID(1), RIF_CID1, RIF_NSEC, RIF_PRIV, RIF_CIDSEL_M)
		RIMUPROT(RIMU_ID(2), RIF_CID1, RIF_NSEC, RIF_PRIV, RIF_CIDSEL_M)
		RIMUPROT(RIMU_ID(3), RIF_CID1, RIF_NSEC, RIF_PRIV, RIF_CIDSEL_M)
		RIMUPROT(RIMU_ID(4), RIF_CID1, RIF_NSEC, RIF_PRIV, RIF_CIDSEL_M)
		RIMUPROT(RIMU_ID(5), RIF_CID1, RIF_NSEC, RIF_PRIV, RIF_CIDSEL_M)
		RIMUPROT(RIMU_ID(6), RIF_CID1, RIF_NSEC, RIF_PRIV, RIF_CIDSEL_M)
		RIMUPROT(RIMU_ID(7), RIF_UNUSED, RIF_NSEC, RIF_NPRIV, RIF_CIDSEL_P)
        	RIMUPROT(RIMU_ID(10), RIF_CID1, RIF_NSEC, RIF_PRIV, RIF_CIDSEL_M)
		RIMUPROT(RIMU_ID(11), RIF_CID4, RIF_NSEC, RIF_PRIV, RIF_CIDSEL_M)
		RIMUPROT(RIMU_ID(12), RIF_CID4, RIF_NSEC, RIF_PRIV, RIF_CIDSEL_M)
	>;
};

&rcc_rif {
	st,protreg = <
		RIFPROT(RIF_RCC_RESOURCE(69), RIF_UNUSED, RIF_UNLOCK, RIF_SEC, RIF_PRIV, RIF_CID2, RIF_SEM_DIS, RIF_CFEN)
		RIFPROT(RIF_RCC_RESOURCE(64), RIF_UNUSED, RIF_UNLOCK, RIF_SEC, RIF_PRIV, RIF_CID2, RIF_SEM_DIS, RIF_CFEN)
		RIFPROT(RIF_RCC_RESOURCE(0), RIF_UNUSED, RIF_UNLOCK, RIF_SEC, RIF_PRIV, RIF_CID2, RIF_SEM_DIS, RIF_CFEN)
		RIFPROT(RIF_RCC_RESOURCE(1), RIF_UNUSED, RIF_UNLOCK, RIF_SEC, RIF_PRIV, RIF_CID2, RIF_SEM_DIS, RIF_CFEN)
		RIFPROT(RIF_RCC_RESOURCE(2), RIF_UNUSED, RIF_UNLOCK, RIF_SEC, RIF_PRIV, RIF_CID2, RIF_SEM_DIS, RIF_CFEN)
		RIFPROT(RIF_RCC_RESOURCE(3), RIF_UNUSED, RIF_UNLOCK, RIF_SEC, RIF_PRIV, RIF_CID2, RIF_SEM_DIS, RIF_CFEN)
		RIFPROT(RIF_RCC_RESOURCE(4), RIF_UNUSED, RIF_UNLOCK, RIF_SEC, RIF_PRIV, RIF_CID2, RIF_SEM_DIS, RIF_CFEN)
		RIFPROT(RIF_RCC_RESOURCE(5), RIF_UNUSED, RIF_UNLOCK, RIF_SEC, RIF_PRIV, RIF_CID2, RIF_SEM_DIS, RIF_CFEN)
		RIFPROT(RIF_RCC_RESOURCE(6), EMPTY_SEMWL, RIF_LOCK, RIF_NSEC, RIF_PRIV, RIF_UNUSED, RIF_SEM_EN, RIF_CFEN)
		RIFPROT(RIF_RCC_RESOURCE(7), RIF_UNUSED, RIF_UNLOCK, RIF_SEC, RIF_PRIV, RIF_CID2, RIF_SEM_DIS, RIF_CFEN)
		RIFPROT(RIF_RCC_RESOURCE(8), RIF_UNUSED, RIF_UNLOCK, RIF_SEC, RIF_PRIV, RIF_CID2, RIF_SEM_DIS, RIF_CFEN)
		RIFPROT(RIF_RCC_RESOURCE(9), EMPTY_SEMWL, RIF_LOCK, RIF_NSEC, RIF_PRIV, RIF_UNUSED, RIF_SEM_EN, RIF_CFEN)
		RIFPROT(RIF_RCC_RESOURCE(10), EMPTY_SEMWL, RIF_LOCK, RIF_NSEC, RIF_PRIV, RIF_UNUSED, RIF_SEM_EN, RIF_CFEN)
		RIFPROT(RIF_RCC_RESOURCE(11), EMPTY_SEMWL, RIF_LOCK, RIF_NSEC, RIF_PRIV, RIF_UNUSED, RIF_SEM_EN, RIF_CFEN)
		RIFPROT(RIF_RCC_RESOURCE(12), EMPTY_SEMWL, RIF_LOCK, RIF_NSEC, RIF_PRIV, RIF_UNUSED, RIF_SEM_EN, RIF_CFEN)
		RIFPROT(RIF_RCC_RESOURCE(13), RIF_UNUSED, RIF_UNLOCK, RIF_SEC, RIF_PRIV, RIF_CID2, RIF_SEM_DIS, RIF_CFEN)
		RIFPROT(RIF_RCC_RESOURCE(14), RIF_UNUSED, RIF_UNLOCK, RIF_SEC, RIF_PRIV, RIF_CID2, RIF_SEM_DIS, RIF_CFEN)
		RIFPROT(RIF_RCC_RESOURCE(16), RIF_UNUSED, RIF_UNLOCK, RIF_SEC, RIF_PRIV, RIF_CID2, RIF_SEM_DIS, RIF_CFEN)
		RIFPROT(RIF_RCC_RESOURCE(17), EMPTY_SEMWL, RIF_LOCK, RIF_NSEC, RIF_PRIV, RIF_UNUSED, RIF_SEM_EN, RIF_CFEN)
		RIFPROT(RIF_RCC_RESOURCE(18), RIF_UNUSED, RIF_UNLOCK, RIF_SEC, RIF_PRIV, RIF_CID2, RIF_SEM_DIS, RIF_CFEN)
		RIFPROT(RIF_RCC_RESOURCE(19), RIF_UNUSED, RIF_UNLOCK, RIF_SEC, RIF_PRIV, RIF_CID2, RIF_SEM_DIS, RIF_CFEN)
		RIFPROT(RIF_RCC_RESOURCE(20), EMPTY_SEMWL, RIF_LOCK, RIF_NSEC, RIF_PRIV, RIF_UNUSED, RIF_SEM_EN, RIF_CFEN)
		RIFPROT(RIF_RCC_RESOURCE(21), RIF_UNUSED, RIF_UNLOCK, RIF_SEC, RIF_PRIV, RIF_CID2, RIF_SEM_DIS, RIF_CFEN)
		RIFPROT(RIF_RCC_RESOURCE(22), RIF_UNUSED, RIF_UNLOCK, RIF_SEC, RIF_PRIV, RIF_CID2, RIF_SEM_DIS, RIF_CFEN)
		RIFPROT(RIF_RCC_RESOURCE(23), RIF_UNUSED, RIF_UNLOCK, RIF_SEC, RIF_PRIV, RIF_CID2, RIF_SEM_DIS, RIF_CFEN)
		RIFPROT(RIF_RCC_RESOURCE(24), EMPTY_SEMWL, RIF_LOCK, RIF_NSEC, RIF_PRIV, RIF_UNUSED, RIF_SEM_EN, RIF_CFEN)
		RIFPROT(RIF_RCC_RESOURCE(25), EMPTY_SEMWL, RIF_LOCK, RIF_NSEC, RIF_PRIV, RIF_UNUSED, RIF_SEM_EN, RIF_CFEN)
		RIFPROT(RIF_RCC_RESOURCE(26), EMPTY_SEMWL, RIF_LOCK, RIF_NSEC, RIF_PRIV, RIF_UNUSED, RIF_SEM_EN, RIF_CFEN)
		RIFPROT(RIF_RCC_RESOURCE(27), RIF_UNUSED, RIF_UNLOCK, RIF_SEC, RIF_PRIV, RIF_CID2, RIF_SEM_DIS, RIF_CFEN)
		RIFPROT(RIF_RCC_RESOURCE(29), RIF_UNUSED, RIF_UNLOCK, RIF_SEC, RIF_PRIV, RIF_CID2, RIF_SEM_DIS, RIF_CFEN)
		RIFPROT(RIF_RCC_RESOURCE(30), RIF_UNUSED, RIF_UNLOCK, RIF_SEC, RIF_PRIV, RIF_CID2, RIF_SEM_DIS, RIF_CFEN)
		RIFPROT(RIF_RCC_RESOURCE(31), RIF_UNUSED, RIF_UNLOCK, RIF_SEC, RIF_PRIV, RIF_CID2, RIF_SEM_DIS, RIF_CFEN)
		RIFPROT(RIF_RCC_RESOURCE(33), RIF_UNUSED, RIF_LOCK, RIF_SEC, RIF_PRIV, RIF_CID1, RIF_SEM_DIS, RIF_CFEN)
		RIFPROT(RIF_RCC_RESOURCE(36), EMPTY_SEMWL, RIF_LOCK, RIF_NSEC, RIF_PRIV, RIF_UNUSED, RIF_SEM_EN, RIF_CFEN)
		RIFPROT(RIF_RCC_RESOURCE(37), EMPTY_SEMWL, RIF_LOCK, RIF_NSEC, RIF_PRIV, RIF_UNUSED, RIF_SEM_EN, RIF_CFEN)
		RIFPROT(RIF_RCC_RESOURCE(38), RIF_UNUSED, RIF_UNLOCK, RIF_SEC, RIF_PRIV, RIF_CID2, RIF_SEM_DIS, RIF_CFEN)
		RIFPROT(RIF_RCC_RESOURCE(39), EMPTY_SEMWL, RIF_LOCK, RIF_NSEC, RIF_PRIV, RIF_UNUSED, RIF_SEM_EN, RIF_CFEN)
		RIFPROT(RIF_RCC_RESOURCE(40), RIF_UNUSED, RIF_UNLOCK, RIF_SEC, RIF_PRIV, RIF_CID2, RIF_SEM_DIS, RIF_CFEN)
		RIFPROT(RIF_RCC_RESOURCE(41), RIF_UNUSED, RIF_UNLOCK, RIF_SEC, RIF_PRIV, RIF_CID2, RIF_SEM_DIS, RIF_CFEN)
		RIFPROT(RIF_RCC_RESOURCE(42), RIF_UNUSED, RIF_UNLOCK, RIF_SEC, RIF_PRIV, RIF_CID2, RIF_SEM_DIS, RIF_CFEN)
		RIFPROT(RIF_RCC_RESOURCE(43), RIF_UNUSED, RIF_UNLOCK, RIF_SEC, RIF_PRIV, RIF_CID2, RIF_SEM_DIS, RIF_CFEN)
		RIFPROT(RIF_RCC_RESOURCE(44), RIF_UNUSED, RIF_UNLOCK, RIF_SEC, RIF_PRIV, RIF_CID2, RIF_SEM_DIS, RIF_CFEN)
		RIFPROT(RIF_RCC_RESOURCE(45), RIF_UNUSED, RIF_UNLOCK, RIF_SEC, RIF_PRIV, RIF_CID2, RIF_SEM_DIS, RIF_CFEN)
		RIFPROT(RIF_RCC_RESOURCE(46), RIF_UNUSED, RIF_UNLOCK, RIF_SEC, RIF_PRIV, RIF_CID2, RIF_SEM_DIS, RIF_CFEN)
		RIFPROT(RIF_RCC_RESOURCE(47), RIF_UNUSED, RIF_UNLOCK, RIF_SEC, RIF_PRIV, RIF_CID2, RIF_SEM_DIS, RIF_CFEN)
		RIFPROT(RIF_RCC_RESOURCE(48), EMPTY_SEMWL, RIF_LOCK, RIF_NSEC, RIF_PRIV, RIF_UNUSED, RIF_SEM_EN, RIF_CFEN)
		RIFPROT(RIF_RCC_RESOURCE(50), EMPTY_SEMWL, RIF_LOCK, RIF_NSEC, RIF_PRIV, RIF_UNUSED, RIF_SEM_EN, RIF_CFEN)
		RIFPROT(RIF_RCC_RESOURCE(51), RIF_UNUSED, RIF_UNLOCK, RIF_SEC, RIF_PRIV, RIF_CID2, RIF_SEM_DIS, RIF_CFEN)
		RIFPROT(RIF_RCC_RESOURCE(52), RIF_UNUSED, RIF_UNLOCK, RIF_SEC, RIF_PRIV, RIF_CID2, RIF_SEM_DIS, RIF_CFEN)
		RIFPROT(RIF_RCC_RESOURCE(53), RIF_UNUSED, RIF_UNLOCK, RIF_SEC, RIF_PRIV, RIF_CID2, RIF_SEM_DIS, RIF_CFEN)
		RIFPROT(RIF_RCC_RESOURCE(54), RIF_UNUSED, RIF_UNLOCK, RIF_SEC, RIF_PRIV, RIF_CID2, RIF_SEM_DIS, RIF_CFEN)
		RIFPROT(RIF_RCC_RESOURCE(55), EMPTY_SEMWL, RIF_LOCK, RIF_NSEC, RIF_PRIV, RIF_UNUSED, RIF_SEM_EN, RIF_CFEN)
		RIFPROT(RIF_RCC_RESOURCE(56), RIF_UNUSED, RIF_UNLOCK, RIF_SEC, RIF_PRIV, RIF_CID2, RIF_SEM_DIS, RIF_CFEN)
		RIFPROT(RIF_RCC_RESOURCE(57), RIF_UNUSED, RIF_UNLOCK, RIF_SEC, RIF_PRIV, RIF_CID2, RIF_SEM_DIS, RIF_CFEN)
		RIFPROT(RIF_RCC_RESOURCE(58), RIF_UNUSED, RIF_UNLOCK, RIF_SEC, RIF_PRIV, RIF_CID2, RIF_SEM_DIS, RIF_CFEN)
		RIFPROT(RIF_RCC_RESOURCE(61), RIF_UNUSED, RIF_UNLOCK, RIF_SEC, RIF_PRIV, RIF_CID2, RIF_SEM_DIS, RIF_CFEN)
		RIFPROT(RIF_RCC_RESOURCE(62), RIF_UNUSED, RIF_UNLOCK, RIF_SEC, RIF_PRIV, RIF_CID2, RIF_SEM_DIS, RIF_CFEN)
		RIFPROT(RIF_RCC_RESOURCE(63), RIF_UNUSED, RIF_LOCK, RIF_SEC, RIF_PRIV, RIF_CID1, RIF_SEM_DIS, RIF_CFEN)
		RIFPROT(RIF_RCC_RESOURCE(65), RIF_UNUSED, RIF_UNLOCK, RIF_SEC, RIF_PRIV, RIF_CID2, RIF_SEM_DIS, RIF_CFEN)
		RIFPROT(RIF_RCC_RESOURCE(66), RIF_UNUSED, RIF_UNLOCK, RIF_SEC, RIF_PRIV, RIF_CID2, RIF_SEM_DIS, RIF_CFEN)
		RIFPROT(RIF_RCC_RESOURCE(67), RIF_UNUSED, RIF_UNLOCK, RIF_SEC, RIF_PRIV, RIF_CID2, RIF_SEM_DIS, RIF_CFEN)
		RIFPROT(RIF_RCC_RESOURCE(68), RIF_UNUSED, RIF_UNLOCK, RIF_SEC, RIF_PRIV, RIF_CID2, RIF_SEM_DIS, RIF_CFEN)
		RIFPROT(RIF_RCC_RESOURCE(70), RIF_UNUSED, RIF_LOCK, RIF_SEC, RIF_PRIV, RIF_CID1, RIF_SEM_DIS, RIF_CFEN)
		RIFPROT(RIF_RCC_RESOURCE(71), RIF_UNUSED, RIF_UNLOCK, RIF_SEC, RIF_PRIV, RIF_CID2, RIF_SEM_DIS, RIF_CFEN)
		RIFPROT(RIF_RCC_RESOURCE(73), RIF_CID2_BF, RIF_UNLOCK, RIF_SEC, RIF_PRIV, RIF_UNUSED, RIF_SEM_EN, RIF_CFEN)
		RIFPROT(RIF_RCC_RESOURCE(74), RIF_CID1_BF, RIF_LOCK, RIF_SEC, RIF_PRIV, RIF_UNUSED, RIF_SEM_EN, RIF_CFEN)
		RIFPROT(RIF_RCC_RESOURCE(76), RIF_CID2_BF, RIF_UNLOCK, RIF_SEC, RIF_PRIV, RIF_UNUSED, RIF_SEM_EN, RIF_CFEN)
		RIFPROT(RIF_RCC_RESOURCE(77), RIF_CID2_BF, RIF_UNLOCK, RIF_SEC, RIF_PRIV, RIF_UNUSED, RIF_SEM_EN, RIF_CFEN)
		RIFPROT(RIF_RCC_RESOURCE(78), RIF_CID2_BF, RIF_UNLOCK, RIF_SEC, RIF_PRIV, RIF_UNUSED, RIF_SEM_EN, RIF_CFEN)
		RIFPROT(RIF_RCC_RESOURCE(83), RIF_CID2_BF, RIF_UNLOCK, RIF_SEC, RIF_PRIV, RIF_UNUSED, RIF_SEM_EN, RIF_CFEN)
		RIFPROT(RIF_RCC_RESOURCE(84), RIF_CID2_BF, RIF_UNLOCK, RIF_SEC, RIF_PRIV, RIF_UNUSED, RIF_SEM_EN, RIF_CFEN)
		RIFPROT(RIF_RCC_RESOURCE(85), RIF_CID2_BF, RIF_UNLOCK, RIF_SEC, RIF_PRIV, RIF_UNUSED, RIF_SEM_EN, RIF_CFEN)
		RIFPROT(RIF_RCC_RESOURCE(87), RIF_CID2_BF, RIF_UNLOCK, RIF_SEC, RIF_PRIV, RIF_UNUSED, RIF_SEM_EN, RIF_CFEN)
		RIFPROT(RIF_RCC_RESOURCE(90), RIF_CID2_BF, RIF_UNLOCK, RIF_SEC, RIF_PRIV, RIF_UNUSED, RIF_SEM_EN, RIF_CFEN)
		RIFPROT(RIF_RCC_RESOURCE(91), RIF_CID2_BF, RIF_UNLOCK, RIF_SEC, RIF_PRIV, RIF_UNUSED, RIF_SEM_EN, RIF_CFEN)
		RIFPROT(RIF_RCC_RESOURCE(92), RIF_CID2_BF, RIF_UNLOCK, RIF_SEC, RIF_PRIV, RIF_UNUSED, RIF_SEM_EN, RIF_CFEN)
		RIFPROT(RIF_RCC_RESOURCE(93), RIF_CID2_BF, RIF_UNLOCK, RIF_SEC, RIF_PRIV, RIF_UNUSED, RIF_SEM_EN, RIF_CFEN)
		RIFPROT(RIF_RCC_RESOURCE(94), RIF_CID2_BF, RIF_UNLOCK, RIF_SEC, RIF_PRIV, RIF_UNUSED, RIF_SEM_EN, RIF_CFEN)
		RIFPROT(RIF_RCC_RESOURCE(95), RIF_CID2_BF, RIF_UNLOCK, RIF_SEC, RIF_PRIV, RIF_UNUSED, RIF_SEM_EN, RIF_CFEN)
		RIFPROT(RIF_RCC_RESOURCE(96), RIF_CID2_BF, RIF_UNLOCK, RIF_SEC, RIF_PRIV, RIF_UNUSED, RIF_SEM_EN, RIF_CFEN)
		RIFPROT(RIF_RCC_RESOURCE(97), RIF_CID2_BF, RIF_UNLOCK, RIF_SEC, RIF_PRIV, RIF_UNUSED, RIF_SEM_EN, RIF_CFEN)
		RIFPROT(RIF_RCC_RESOURCE(98), RIF_CID2_BF, RIF_UNLOCK, RIF_SEC, RIF_PRIV, RIF_UNUSED, RIF_SEM_EN, RIF_CFEN)
		RIFPROT(RIF_RCC_RESOURCE(101), RIF_CID2_BF, RIF_UNLOCK, RIF_SEC, RIF_PRIV, RIF_UNUSED, RIF_SEM_EN, RIF_CFEN)
		RIFPROT(RIF_RCC_RESOURCE(102), RIF_CID2_BF, RIF_UNLOCK, RIF_SEC, RIF_PRIV, RIF_UNUSED, RIF_SEM_EN, RIF_CFEN)
		RIFPROT(RIF_RCC_RESOURCE(103), RIF_CID1_BF|RIF_CID2_BF, RIF_LOCK, RIF_SEC, RIF_PRIV, RIF_UNUSED, RIF_SEM_EN, RIF_CFEN)
		RIFPROT(RIF_RCC_RESOURCE(104), RIF_CID2_BF, RIF_UNLOCK, RIF_SEC, RIF_PRIV, RIF_UNUSED, RIF_SEM_EN, RIF_CFEN)
		RIFPROT(RIF_RCC_RESOURCE(106), RIF_UNUSED, RIF_LOCK, RIF_SEC, RIF_PRIV, RIF_CID1, RIF_SEM_DIS, RIF_CFEN)
		RIFPROT(RIF_RCC_RESOURCE(108), RIF_UNUSED, RIF_UNLOCK, RIF_SEC, RIF_PRIV, RIF_CID2, RIF_SEM_DIS, RIF_CFEN)
		RIFPROT(RIF_RCC_RESOURCE(109), RIF_UNUSED, RIF_UNLOCK, RIF_SEC, RIF_PRIV, RIF_CID2, RIF_SEM_DIS, RIF_CFEN)
		RIFPROT(RIF_RCC_RESOURCE(110), EMPTY_SEMWL, RIF_LOCK, RIF_NSEC, RIF_NPRIV, RIF_UNUSED, RIF_SEM_EN, RIF_CFEN)
		RIFPROT(RIF_RCC_RESOURCE(112), EMPTY_SEMWL, RIF_LOCK, RIF_NSEC, RIF_NPRIV, RIF_UNUSED, RIF_SEM_EN, RIF_CFEN)
		RIFPROT(RIF_RCC_RESOURCE(113), RIF_CID2_BF, RIF_UNLOCK, RIF_SEC, RIF_PRIV, RIF_UNUSED, RIF_SEM_EN, RIF_CFEN)
	>;
};

&ipcc1 {
	st,protreg = <
		RIFPROT(RIF_IPCC_CPU1_CHANNEL(1), RIF_UNUSED, RIF_UNLOCK, RIF_NSEC, RIF_NPRIV, RIF_CID1, RIF_SEM_DIS, RIF_CFEN)
		RIFPROT(RIF_IPCC_CPU2_CHANNEL(1), RIF_UNUSED, RIF_UNLOCK, RIF_NSEC, RIF_NPRIV, RIF_CID2, RIF_SEM_DIS, RIF_CFEN)
		RIFPROT(RIF_IPCC_CPU1_CHANNEL(2), RIF_UNUSED, RIF_UNLOCK, RIF_NSEC, RIF_NPRIV, RIF_CID1, RIF_SEM_DIS, RIF_CFEN)
		RIFPROT(RIF_IPCC_CPU2_CHANNEL(2), RIF_UNUSED, RIF_UNLOCK, RIF_NSEC, RIF_NPRIV, RIF_CID2, RIF_SEM_DIS, RIF_CFEN)
		RIFPROT(RIF_IPCC_CPU1_CHANNEL(3), RIF_UNUSED, RIF_UNLOCK, RIF_NSEC, RIF_NPRIV, RIF_CID1, RIF_SEM_DIS, RIF_CFEN)
		RIFPROT(RIF_IPCC_CPU2_CHANNEL(3), RIF_UNUSED, RIF_UNLOCK, RIF_NSEC, RIF_NPRIV, RIF_CID2, RIF_SEM_DIS, RIF_CFEN)
		RIFPROT(RIF_IPCC_CPU1_CHANNEL(4), RIF_UNUSED, RIF_UNLOCK, RIF_NSEC, RIF_NPRIV, RIF_CID1, RIF_SEM_DIS, RIF_CFEN)
		RIFPROT(RIF_IPCC_CPU2_CHANNEL(4), RIF_UNUSED, RIF_UNLOCK, RIF_NSEC, RIF_NPRIV, RIF_CID2, RIF_SEM_DIS, RIF_CFEN)
		RIFPROT(RIF_IPCC_CPU1_CHANNEL(5), RIF_UNUSED, RIF_UNLOCK, RIF_NSEC, RIF_NPRIV, RIF_CID1, RIF_SEM_DIS, RIF_CFEN)
		RIFPROT(RIF_IPCC_CPU2_CHANNEL(5), RIF_UNUSED, RIF_UNLOCK, RIF_NSEC, RIF_NPRIV, RIF_CID2, RIF_SEM_DIS, RIF_CFEN)
		RIFPROT(RIF_IPCC_CPU1_CHANNEL(6), RIF_UNUSED, RIF_UNLOCK, RIF_NSEC, RIF_NPRIV, RIF_CID1, RIF_SEM_DIS, RIF_CFEN)
		RIFPROT(RIF_IPCC_CPU2_CHANNEL(6), RIF_UNUSED, RIF_UNLOCK, RIF_NSEC, RIF_NPRIV, RIF_CID2, RIF_SEM_DIS, RIF_CFEN)
		RIFPROT(RIF_IPCC_CPU1_CHANNEL(7), RIF_UNUSED, RIF_UNLOCK, RIF_NSEC, RIF_NPRIV, RIF_CID1, RIF_SEM_DIS, RIF_CFEN)
		RIFPROT(RIF_IPCC_CPU2_CHANNEL(7), RIF_UNUSED, RIF_UNLOCK, RIF_NSEC, RIF_NPRIV, RIF_CID2, RIF_SEM_DIS, RIF_CFEN)
		RIFPROT(RIF_IPCC_CPU1_CHANNEL(8), RIF_UNUSED, RIF_UNLOCK, RIF_NSEC, RIF_NPRIV, RIF_CID1, RIF_SEM_DIS, RIF_CFEN)
		RIFPROT(RIF_IPCC_CPU2_CHANNEL(8), RIF_UNUSED, RIF_UNLOCK, RIF_NSEC, RIF_NPRIV, RIF_CID2, RIF_SEM_DIS, RIF_CFEN)
		RIFPROT(RIF_IPCC_CPU1_CHANNEL(9), RIF_UNUSED, RIF_UNLOCK, RIF_NSEC, RIF_NPRIV, RIF_CID1, RIF_SEM_DIS, RIF_CFEN)
		RIFPROT(RIF_IPCC_CPU2_CHANNEL(9), RIF_UNUSED, RIF_UNLOCK, RIF_NSEC, RIF_NPRIV, RIF_CID2, RIF_SEM_DIS, RIF_CFEN)
		RIFPROT(RIF_IPCC_CPU1_CHANNEL(10), RIF_UNUSED, RIF_UNLOCK, RIF_NSEC, RIF_NPRIV, RIF_CID1, RIF_SEM_DIS, RIF_CFEN)
		RIFPROT(RIF_IPCC_CPU2_CHANNEL(10), RIF_UNUSED, RIF_UNLOCK, RIF_NSEC, RIF_NPRIV, RIF_CID2, RIF_SEM_DIS, RIF_CFEN)
		RIFPROT(RIF_IPCC_CPU1_CHANNEL(11), RIF_UNUSED, RIF_UNLOCK, RIF_NSEC, RIF_NPRIV, RIF_CID1, RIF_SEM_DIS, RIF_CFEN)
		RIFPROT(RIF_IPCC_CPU2_CHANNEL(11), RIF_UNUSED, RIF_UNLOCK, RIF_NSEC, RIF_NPRIV, RIF_CID2, RIF_SEM_DIS, RIF_CFEN)
		RIFPROT(RIF_IPCC_CPU1_CHANNEL(12), RIF_UNUSED, RIF_UNLOCK, RIF_NSEC, RIF_NPRIV, RIF_CID1, RIF_SEM_DIS, RIF_CFEN)
		RIFPROT(RIF_IPCC_CPU2_CHANNEL(12), RIF_UNUSED, RIF_UNLOCK, RIF_NSEC, RIF_NPRIV, RIF_CID2, RIF_SEM_DIS, RIF_CFEN)
		RIFPROT(RIF_IPCC_CPU1_CHANNEL(13), RIF_UNUSED, RIF_UNLOCK, RIF_NSEC, RIF_PRIV, RIF_CID1, RIF_SEM_DIS, RIF_CFEN)
		RIFPROT(RIF_IPCC_CPU2_CHANNEL(13), RIF_UNUSED, RIF_UNLOCK, RIF_NSEC, RIF_NPRIV, RIF_CID2, RIF_SEM_DIS, RIF_CFEN)
		RIFPROT(RIF_IPCC_CPU1_CHANNEL(14), RIF_UNUSED, RIF_UNLOCK, RIF_SEC, RIF_NPRIV, RIF_CID1, RIF_SEM_DIS, RIF_CFEN)
		RIFPROT(RIF_IPCC_CPU2_CHANNEL(14), RIF_UNUSED, RIF_UNLOCK, RIF_SEC, RIF_PRIV, RIF_CID2, RIF_SEM_DIS, RIF_CFEN)
		RIFPROT(RIF_IPCC_CPU1_CHANNEL(15), RIF_UNUSED, RIF_UNLOCK, RIF_SEC, RIF_PRIV, RIF_CID1, RIF_SEM_DIS, RIF_CFEN)
		RIFPROT(RIF_IPCC_CPU2_CHANNEL(15), RIF_UNUSED, RIF_UNLOCK, RIF_SEC, RIF_PRIV, RIF_CID2, RIF_SEM_DIS, RIF_CFEN)
		RIFPROT(RIF_IPCC_CPU1_CHANNEL(16), RIF_UNUSED, RIF_UNLOCK, RIF_NSEC, RIF_PRIV, RIF_CID1, RIF_SEM_DIS, RIF_CFEN)
		RIFPROT(RIF_IPCC_CPU2_CHANNEL(16), RIF_UNUSED, RIF_UNLOCK, RIF_SEC, RIF_PRIV, RIF_CID2, RIF_SEM_DIS, RIF_CFEN)
	>;
};

&tfa_bl31 {
	st,protreg = <RISABPROT(RIF_DDCID_DIS, RIF_UNUSED, RIF_SEC, RIF_NPRIV, RIF_CFEN, RIF_CID1_BF, RIF_CID1_BF, RIF_CID1_BF)>;
};

&hpdma_lli {
	st,protreg = <RISABPROT(RIF_DDCID_DIS, RIF_UNUSED, RIF_NSEC, RIF_NPRIV, RIF_CFEN, RIF_CID1_BF, RIF_CID1_BF, RIF_CID1_BF)>;
};

&bsec_mirror {
	st,protreg = <RISABPROT(RIF_DDCID_DIS, RIF_UNUSED, RIF_NSEC, RIF_NPRIV, RIF_CFEN, RIF_CID1_BF|RIF_CID2_BF, RIF_CID2_BF, RIF_CID1_BF|RIF_CID2_BF)>;
};

&cm33_sram1 {
	st,protreg = <RISABPROT(RIF_DDCID_DIS, RIF_UNUSED, RIF_SEC, RIF_NPRIV, RIF_CFEN, RIF_CID2_BF, RIF_CID2_BF, RIF_CID2_BF)>;
};

&tfm_shared_data {
	st,protreg = <RISABPROT(RIF_DDCID_DIS, RIF_UNUSED, RIF_SEC, RIF_NPRIV, RIF_CFEN, RIF_CID2_BF, RIF_CID2_BF, RIF_CID2_BF)>;
};

&cm33_retram {
	st,protreg = <RISABPROT(RIF_DDCID_DIS, RIF_UNUSED, RIF_SEC, RIF_NPRIV, RIF_CFEN, RIF_CID2_BF, RIF_CID2_BF, RIF_CID2_BF)>;
};

&ddr_param {
	st,protreg = <RISABPROT(RIF_DDCID_DIS, RIF_UNUSED, RIF_SEC, RIF_NPRIV, RIF_CFEN, RIF_CID2_BF, RIF_CID2_BF, RIF_CID2_BF)>;
};

&risab3 {
	st,errata-ahbrisab;
	st,srwiad;
	memory-region = <&bsec_mirror>, <&cm33_sram1>, <&tfm_shared_data>;
};

&risab5 {
	st,errata-ahbrisab;
	st,srwiad;
	memory-region = <&cm33_retram>, <&ddr_param>;
};

&bl31_lowpower {
	st,protreg = <RISAFPROT(RISAF_REG_ID(1), RIF_CID1_BF, RIF_CID1_BF, RIF_CID1_BF, RIF_SEC, RIF_ENC_DIS, RIF_BREN_EN)>;
};

&tfm_its {
	st,protreg = <RISAFPROT(RISAF_REG_ID(2), RIF_CID2_BF, RIF_CID2_BF, RIF_CID2_BF, RIF_SEC, RIF_ENC_DIS, RIF_BREN_EN)>;
};

&risaf1 {
	memory-region = <&bl31_lowpower>, <&tfm_its>;
};

&tfm_code {
	st,protreg = <RISAFPROT(RISAF_REG_ID(1), RIF_CID2_BF, RIF_CID2_BF, RIF_UNUSED, RIF_SEC, RIF_ENC_EN, RIF_BREN_EN)>;
};

&cm33_cube_fw {
	st,protreg = <RISAFPROT(RISAF_REG_ID(2), RIF_CID2_BF, RIF_CID2_BF, RIF_UNUSED, RIF_NSEC, RIF_ENC_DIS, RIF_BREN_EN)>;
};

&tfm_data {
	st,protreg = <RISAFPROT(RISAF_REG_ID(3), RIF_CID2_BF, RIF_CID2_BF, RIF_UNUSED, RIF_SEC, RIF_ENC_EN, RIF_BREN_EN)>;
};

&cm33_cube_data {
	st,protreg = <RISAFPROT(RISAF_REG_ID(4), RIF_CID2_BF, RIF_CID2_BF, RIF_UNUSED, RIF_NSEC, RIF_ENC_DIS, RIF_BREN_EN)>;
};

&ipc_shmem {
	st,protreg = <RISAFPROT(RISAF_REG_ID(5), RIF_CID1_BF|RIF_CID2_BF, RIF_CID1_BF|RIF_CID2_BF, RIF_UNUSED, RIF_NSEC, RIF_ENC_DIS, RIF_BREN_EN)>;
};

&ltdc_m33_layer {
	st,protreg = <RISAFPROT(RISAF_REG_ID(6), RIF_CID2_BF|RIF_CID4_BF, RIF_CID2_BF|RIF_CID4_BF, RIF_UNUSED, RIF_NSEC, RIF_ENC_DIS, RIF_BREN_EN)>;
};

&fwu_shmem {
	st,protreg = <RISAFPROT(RISAF_REG_ID(7), RIF_CID1_BF|RIF_CID2_BF, RIF_CID1_BF|RIF_CID2_BF, RIF_UNUSED, RIF_NSEC, RIF_ENC_DIS, RIF_BREN_EN)>;
};

&bl31_context {
	st,protreg = <RISAFPROT(RISAF_REG_ID(8), RIF_CID1_BF, RIF_CID1_BF, RIF_CID1_BF, RIF_SEC, RIF_ENC_EN, RIF_BREN_EN)>;
};

&op_tee {
	st,protreg = <RISAFPROT(RISAF_REG_ID(9), RIF_CID1_BF, RIF_CID1_BF, RIF_UNUSED, RIF_SEC, RIF_ENC_EN, RIF_BREN_EN)>;
};

&linuxkernel1 {
	st,protreg = <RISAFPROT(RISAF_REG_ID(10), RIF_CID1_BF|RIF_CID4_BF, RIF_CID1_BF|RIF_CID4_BF, RIF_UNUSED, RIF_NSEC, RIF_ENC_DIS, RIF_BREN_EN)>;
};

&risaf4 {
	memory-region = <&tfm_code>, <&cm33_cube_fw>, <&tfm_data>, <&cm33_cube_data>, <&ipc_shmem>, <&ltdc_m33_layer>, <&fwu_shmem>, <&bl31_context>, <&op_tee>, <&linuxkernel1>;
};

&rng1 {
	access-controllers = <&rifsc RIFPROT(STM32MP21_RIFSC_RNG1_ID, RIF_CID1_BF|RIF_CID2_BF, RIF_LOCK, RIF_SEC, RIF_PRIV, RIF_UNUSED, RIF_SEM_EN, RIF_CFEN)>;
};

